AUTOSAR XML (schema 00046)
package /ComponentTypes
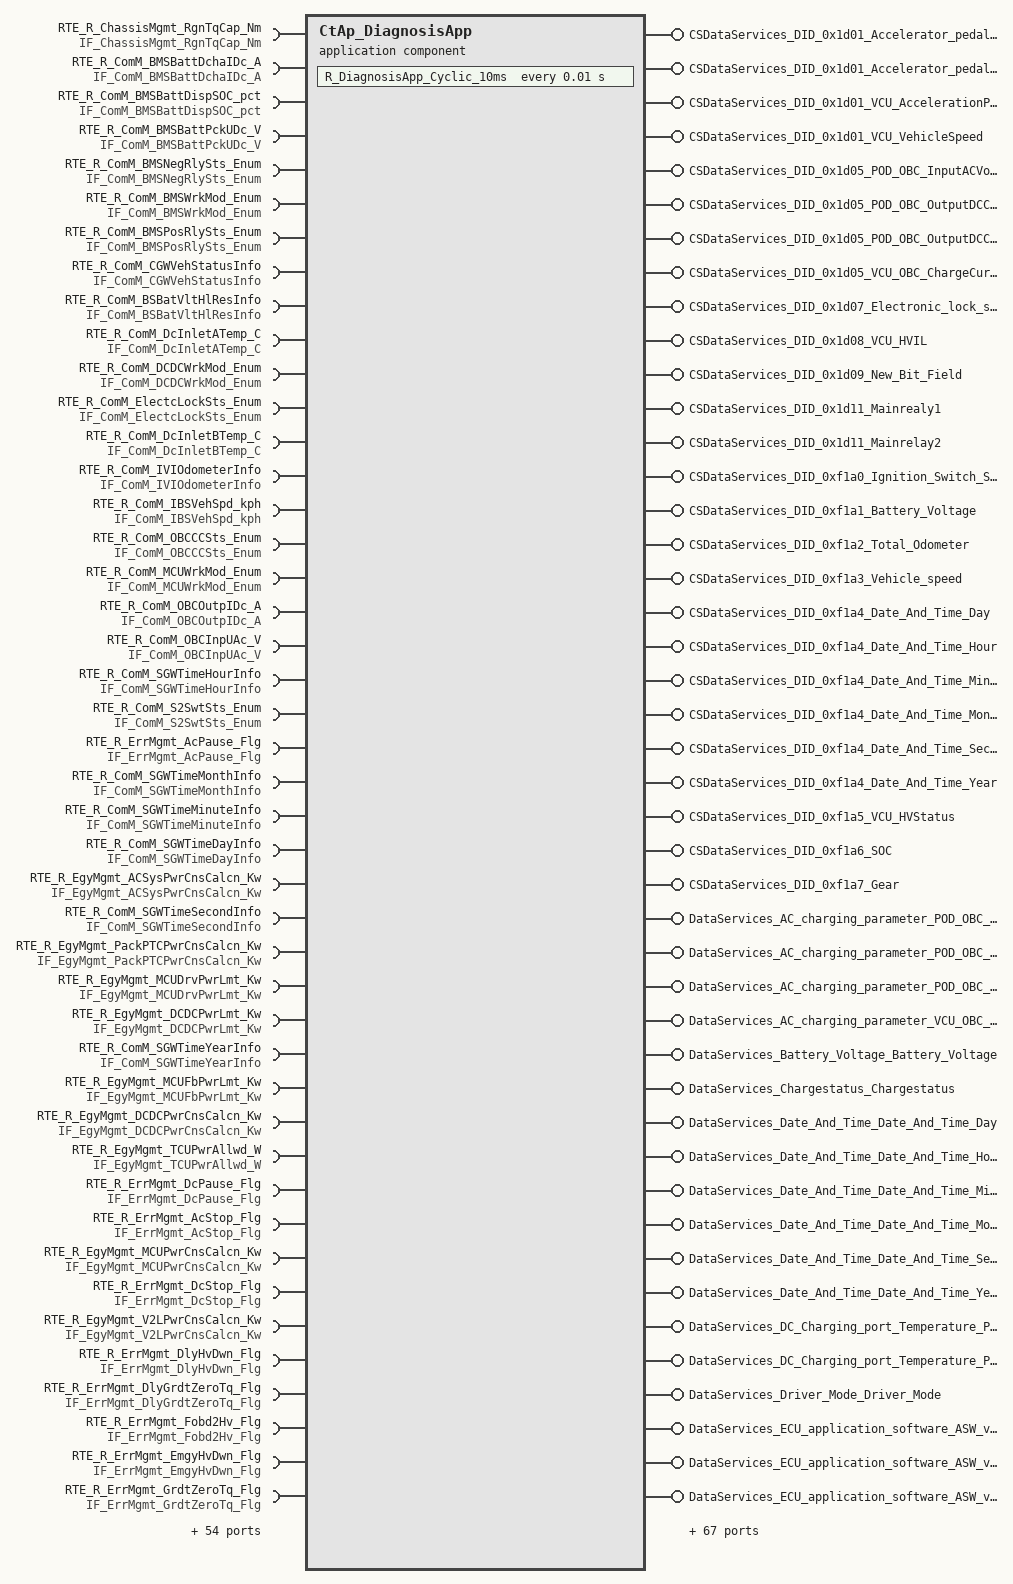
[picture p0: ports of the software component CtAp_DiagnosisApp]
  application sw component type CtAp_DiagnosisApp
    67 x require port:
      RTE_R_ChassisMgmt_RgnTqCap_Nm: nonqueued-receiver-com-spec{data-element=tec_ChassisMgmt_RgnTqCap_Nm, filter=data-filter-type=ALWAYS, init-value=0}, required-interface=IF_ChassisMgmt_RgnTqCap_Nm
      RTE_R_ComM_BMSBattDchaIDc_A: nonqueued-receiver-com-spec{data-element=tec_ComM_BMSBattDchaIDc_A, filter=data-filter-type=ALWAYS, init-value=0}, required-interface=IF_ComM_BMSBattDchaIDc_A
      RTE_R_ComM_BMSBattDispSOC_pct: nonqueued-receiver-com-spec{data-element=tec_ComM_BMSBattDispSOC_pct, filter=data-filter-type=ALWAYS, init-value=0}, required-interface=IF_ComM_BMSBattDispSOC_pct
      RTE_R_ComM_BMSBattPckUDc_V: nonqueued-receiver-com-spec{data-element=tec_ComM_BMSBattPckUDc_V, filter=data-filter-type=ALWAYS, init-value=0}, required-interface=IF_ComM_BMSBattPckUDc_V
      RTE_R_ComM_BMSNegRlySts_Enum: nonqueued-receiver-com-spec{data-element=tec_ComM_BMSNegRlySts_Enum, filter=data-filter-type=ALWAYS, init-value=0}, required-interface=IF_ComM_BMSNegRlySts_Enum
      RTE_R_ComM_BMSWrkMod_Enum: nonqueued-receiver-com-spec{data-element=tec_ComM_BMSWrkMod_Enum, filter=data-filter-type=ALWAYS, init-value=0}, required-interface=IF_ComM_BMSWrkMod_Enum
      RTE_R_ComM_BMSPosRlySts_Enum: nonqueued-receiver-com-spec{data-element=tec_ComM_BMSPosRlySts_Enum, filter=data-filter-type=ALWAYS, init-value=0}, required-interface=IF_ComM_BMSPosRlySts_Enum
      RTE_R_ComM_CGWVehStatusInfo: nonqueued-receiver-com-spec{data-element=tec_ComM_CGWVehStatusInfo, filter=data-filter-type=ALWAYS, init-value=0}, required-interface=IF_ComM_CGWVehStatusInfo
      RTE_R_ComM_BSBatVltHlResInfo: nonqueued-receiver-com-spec{data-element=tec_ComM_BSBatVltHlResInfo, filter=data-filter-type=ALWAYS, init-value=0}, required-interface=IF_ComM_BSBatVltHlResInfo
      RTE_R_ComM_DcInletATemp_C: nonqueued-receiver-com-spec{data-element=tec_ComM_DcInletATemp_C, filter=data-filter-type=ALWAYS, init-value=0}, required-interface=IF_ComM_DcInletATemp_C
      RTE_R_ComM_DCDCWrkMod_Enum: nonqueued-receiver-com-spec{data-element=tec_ComM_DCDCWrkMod_Enum, filter=data-filter-type=ALWAYS, init-value=0}, required-interface=IF_ComM_DCDCWrkMod_Enum
      RTE_R_ComM_ElectcLockSts_Enum: nonqueued-receiver-com-spec{data-element=tec_ComM_ElectcLockSts_Enum, filter=data-filter-type=ALWAYS, init-value=0}, required-interface=IF_ComM_ElectcLockSts_Enum
      RTE_R_ComM_DcInletBTemp_C: nonqueued-receiver-com-spec{data-element=tec_ComM_DcInletBTemp_C, filter=data-filter-type=ALWAYS, init-value=0}, required-interface=IF_ComM_DcInletBTemp_C
      RTE_R_ComM_IVIOdometerInfo: nonqueued-receiver-com-spec{data-element=tec_ComM_IVIOdometerInfo, filter=data-filter-type=ALWAYS, init-value=0}, required-interface=IF_ComM_IVIOdometerInfo
      RTE_R_ComM_IBSVehSpd_kph: nonqueued-receiver-com-spec{data-element=tec_ComM_IBSVehSpd_kph, filter=data-filter-type=ALWAYS, init-value=0}, required-interface=IF_ComM_IBSVehSpd_kph
      RTE_R_ComM_OBCCCSts_Enum: nonqueued-receiver-com-spec{data-element=tec_ComM_OBCCCSts_Enum, filter=data-filter-type=ALWAYS, init-value=0}, required-interface=IF_ComM_OBCCCSts_Enum
      RTE_R_ComM_MCUWrkMod_Enum: nonqueued-receiver-com-spec{data-element=tec_ComM_MCUWrkMod_Enum, filter=data-filter-type=ALWAYS, init-value=0}, required-interface=IF_ComM_MCUWrkMod_Enum
      RTE_R_ComM_OBCOutpIDc_A: nonqueued-receiver-com-spec{data-element=tec_ComM_OBCOutpIDc_A, filter=data-filter-type=ALWAYS, init-value=0}, required-interface=IF_ComM_OBCOutpIDc_A
      RTE_R_ComM_OBCInpUAc_V: nonqueued-receiver-com-spec{data-element=tec_ComM_OBCInpUAc_V, filter=data-filter-type=ALWAYS, init-value=0}, required-interface=IF_ComM_OBCInpUAc_V
      RTE_R_ComM_SGWTimeHourInfo: nonqueued-receiver-com-spec{data-element=tec_ComM_SGWTimeHourInfo, filter=data-filter-type=ALWAYS, init-value=0}, required-interface=IF_ComM_SGWTimeHourInfo
      RTE_R_ComM_S2SwtSts_Enum: nonqueued-receiver-com-spec{data-element=tec_ComM_S2SwtSts_Enum, filter=data-filter-type=ALWAYS, init-value=0}, required-interface=IF_ComM_S2SwtSts_Enum
      RTE_R_ErrMgmt_AcPause_Flg: nonqueued-receiver-com-spec{data-element=tec_ErrMgmt_AcPause_Flg, filter=data-filter-type=ALWAYS, init-value=0}, required-interface=IF_ErrMgmt_AcPause_Flg
      RTE_R_ComM_SGWTimeMonthInfo: nonqueued-receiver-com-spec{data-element=tec_ComM_SGWTimeMonthInfo, filter=data-filter-type=ALWAYS, init-value=0}, required-interface=IF_ComM_SGWTimeMonthInfo
      RTE_R_ComM_SGWTimeMinuteInfo: nonqueued-receiver-com-spec{data-element=tec_ComM_SGWTimeMinuteInfo, filter=data-filter-type=ALWAYS, init-value=0}, required-interface=IF_ComM_SGWTimeMinuteInfo
      RTE_R_ComM_SGWTimeDayInfo: nonqueued-receiver-com-spec{data-element=tec_ComM_SGWTimeDayInfo, filter=data-filter-type=ALWAYS, init-value=0}, required-interface=IF_ComM_SGWTimeDayInfo
      RTE_R_EgyMgmt_ACSysPwrCnsCalcn_Kw: nonqueued-receiver-com-spec{data-element=tec_EgyMgmt_ACSysPwrCnsCalcn_Kw, filter=data-filter-type=ALWAYS, init-value=0}, required-interface=IF_EgyMgmt_ACSysPwrCnsCalcn_Kw
      RTE_R_ComM_SGWTimeSecondInfo: nonqueued-receiver-com-spec{data-element=tec_ComM_SGWTimeSecondInfo, filter=data-filter-type=ALWAYS, init-value=0}, required-interface=IF_ComM_SGWTimeSecondInfo
      RTE_R_EgyMgmt_PackPTCPwrCnsCalcn_Kw: nonqueued-receiver-com-spec{data-element=tec_EgyMgmt_PackPTCPwrCnsCalcn_Kw, filter=data-filter-type=ALWAYS, init-value=0}, required-interface=IF_EgyMgmt_PackPTCPwrCnsCalcn_Kw
      RTE_R_EgyMgmt_MCUDrvPwrLmt_Kw: nonqueued-receiver-com-spec{data-element=tec_EgyMgmt_MCUDrvPwrLmt_Kw, filter=data-filter-type=ALWAYS, init-value=0}, required-interface=IF_EgyMgmt_MCUDrvPwrLmt_Kw
      RTE_R_EgyMgmt_DCDCPwrLmt_Kw: nonqueued-receiver-com-spec{data-element=tec_EgyMgmt_DCDCPwrLmt_Kw, filter=data-filter-type=ALWAYS, init-value=0}, required-interface=IF_EgyMgmt_DCDCPwrLmt_Kw
      RTE_R_ComM_SGWTimeYearInfo: nonqueued-receiver-com-spec{data-element=tec_ComM_SGWTimeYearInfo, filter=data-filter-type=ALWAYS, init-value=0}, required-interface=IF_ComM_SGWTimeYearInfo
      RTE_R_EgyMgmt_MCUFbPwrLmt_Kw: nonqueued-receiver-com-spec{data-element=tec_EgyMgmt_MCUFbPwrLmt_Kw, filter=data-filter-type=ALWAYS, init-value=0}, required-interface=IF_EgyMgmt_MCUFbPwrLmt_Kw
      RTE_R_EgyMgmt_DCDCPwrCnsCalcn_Kw: nonqueued-receiver-com-spec{data-element=tec_EgyMgmt_DCDCPwrCnsCalcn_Kw, filter=data-filter-type=ALWAYS, init-value=0}, required-interface=IF_EgyMgmt_DCDCPwrCnsCalcn_Kw
      RTE_R_EgyMgmt_TCUPwrAllwd_W: nonqueued-receiver-com-spec{data-element=tec_EgyMgmt_TCUPwrAllwd_W, filter=data-filter-type=ALWAYS, init-value=0}, required-interface=IF_EgyMgmt_TCUPwrAllwd_W
      RTE_R_ErrMgmt_DcPause_Flg: nonqueued-receiver-com-spec{data-element=tec_ErrMgmt_DcPause_Flg, filter=data-filter-type=ALWAYS, init-value=0}, required-interface=IF_ErrMgmt_DcPause_Flg
      RTE_R_ErrMgmt_AcStop_Flg: nonqueued-receiver-com-spec{data-element=tec_ErrMgmt_AcStop_Flg, filter=data-filter-type=ALWAYS, init-value=0}, required-interface=IF_ErrMgmt_AcStop_Flg
      RTE_R_EgyMgmt_MCUPwrCnsCalcn_Kw: nonqueued-receiver-com-spec{data-element=tec_EgyMgmt_MCUPwrCnsCalcn_Kw, filter=data-filter-type=ALWAYS, init-value=0}, required-interface=IF_EgyMgmt_MCUPwrCnsCalcn_Kw
      RTE_R_ErrMgmt_DcStop_Flg: nonqueued-receiver-com-spec{data-element=tec_ErrMgmt_DcStop_Flg, filter=data-filter-type=ALWAYS, init-value=0}, required-interface=IF_ErrMgmt_DcStop_Flg
      RTE_R_EgyMgmt_V2LPwrCnsCalcn_Kw: nonqueued-receiver-com-spec{data-element=tec_EgyMgmt_V2LPwrCnsCalcn_Kw, filter=data-filter-type=ALWAYS, init-value=0}, required-interface=IF_EgyMgmt_V2LPwrCnsCalcn_Kw
      RTE_R_ErrMgmt_DlyHvDwn_Flg: nonqueued-receiver-com-spec{data-element=tec_ErrMgmt_DlyHvDwn_Flg, filter=data-filter-type=ALWAYS, init-value=0}, required-interface=IF_ErrMgmt_DlyHvDwn_Flg
      RTE_R_ErrMgmt_DlyGrdtZeroTq_Flg: nonqueued-receiver-com-spec{data-element=tec_ErrMgmt_DlyGrdtZeroTq_Flg, filter=data-filter-type=ALWAYS, init-value=0}, required-interface=IF_ErrMgmt_DlyGrdtZeroTq_Flg
      RTE_R_ErrMgmt_Fobd2Hv_Flg: nonqueued-receiver-com-spec{data-element=tec_ErrMgmt_Fobd2Hv_Flg, filter=data-filter-type=ALWAYS, init-value=0}, required-interface=IF_ErrMgmt_Fobd2Hv_Flg
      RTE_R_ErrMgmt_EmgyHvDwn_Flg: nonqueued-receiver-com-spec{data-element=tec_ErrMgmt_EmgyHvDwn_Flg, filter=data-filter-type=ALWAYS, init-value=0}, required-interface=IF_ErrMgmt_EmgyHvDwn_Flg
      RTE_R_ErrMgmt_GrdtZeroTq_Flg: nonqueued-receiver-com-spec{data-element=tec_ErrMgmt_GrdtZeroTq_Flg, filter=data-filter-type=ALWAYS, init-value=0}, required-interface=IF_ErrMgmt_GrdtZeroTq_Flg
      RTE_R_ErrMgmt_FobdEgyRcov_Flg: nonqueued-receiver-com-spec{data-element=tec_ErrMgmt_FobdEgyRcov_Flg, filter=data-filter-type=ALWAYS, init-value=0}, required-interface=IF_ErrMgmt_FobdEgyRcov_Flg
      RTE_R_ErrMgmt_ImdtZeroTq_Flg: nonqueued-receiver-com-spec{data-element=tec_ErrMgmt_ImdtZeroTq_Flg, filter=data-filter-type=ALWAYS, init-value=0}, required-interface=IF_ErrMgmt_ImdtZeroTq_Flg
      RTE_R_ErrMgmt_V2LStop_Flg: nonqueued-receiver-com-spec{data-element=tec_ErrMgmt_V2LStop_Flg, filter=data-filter-type=ALWAYS, init-value=0}, required-interface=IF_ErrMgmt_V2LStop_Flg
      RTE_R_ErrMgmt_HvDwn_Flg: nonqueued-receiver-com-spec{data-element=tec_ErrMgmt_HvDwn_Flg, filter=data-filter-type=ALWAYS, init-value=0}, required-interface=IF_ErrMgmt_HvDwn_Flg
      RTE_R_ErrMgmt_VehSpdLimErrLv5_Flg: nonqueued-receiver-com-spec{data-element=tec_ErrMgmt_VehSpdLimErrLv5_Flg, filter=data-filter-type=ALWAYS, init-value=0}, required-interface=IF_ErrMgmt_VehSpdLimErrLv5_Flg
      RTE_R_ErrMgmt_VehErrLvl_Enum: nonqueued-receiver-com-spec{data-element=tec_ErrMgmt_VehErrLvl_Enum, filter=data-filter-type=ALWAYS, init-value=0}, required-interface=IF_ErrMgmt_VehErrLvl_Enum
      RTE_R_FctSftyMon_ActGear_Enum: nonqueued-receiver-com-spec{data-element=tec_FctSftyMon_ActGear_Enum, filter=data-filter-type=ALWAYS, init-value=0}, required-interface=IF_FctSftyMon_ActGear_Enum
      RTE_R_ErrMgmt_VehSpdLimErrLv6_Flg: nonqueued-receiver-com-spec{data-element=tec_ErrMgmt_VehSpdLimErrLv6_Flg, filter=data-filter-type=ALWAYS, init-value=0}, required-interface=IF_ErrMgmt_VehSpdLimErrLv6_Flg
      RTE_R_HvMgmt_ReqModBMS_Enum: nonqueued-receiver-com-spec{data-element=tec_HvMgmt_ReqModBMS_Enum, filter=data-filter-type=ALWAYS, init-value=0}, required-interface=IF_HvMgmt_ReqModBMS_Enum
      RTE_R_IOAbs_AccrPedlRdnRaw_mV: nonqueued-receiver-com-spec{data-element=tec_IOAbs_AccrPedlRdnRaw_mV, filter=data-filter-type=ALWAYS, init-value=0}, required-interface=IF_IOAbs_AccrPedlRdnRaw_mV
      RTE_R_IOAbs_AccrPedlMaiRaw_mV: nonqueued-receiver-com-spec{data-element=tec_IOAbs_AccrPedlMaiRaw_mV, filter=data-filter-type=ALWAYS, init-value=0}, required-interface=IF_IOAbs_AccrPedlMaiRaw_mV
      RTE_R_IOAbs_BSBattUDc_V: nonqueued-receiver-com-spec{data-element=tec_IOAbs_BSBattUDc_V, filter=data-filter-type=ALWAYS, init-value=0}, required-interface=IF_IOAbs_BSBattUDc_V
      RTE_R_ModMgmt_ActDrvMod_Enum: nonqueued-receiver-com-spec{data-element=tec_ModMgmt_ActDrvMod_Enum, filter=data-filter-type=ALWAYS, init-value=0}, required-interface=IF_ModMgmt_ActDrvMod_Enum
      RTE_R_IOAbs_HVILPwmFrq_Hz: nonqueued-receiver-com-spec{data-element=tec_IOAbs_HVILPwmFrq_Hz, filter=data-filter-type=ALWAYS, init-value=0}, required-interface=IF_IOAbs_HVILPwmFrq_Hz
      RTE_R_ModMgmt_HvSts_Enum: nonqueued-receiver-com-spec{data-element=tec_ModMgmt_HvSts_Enum, filter=data-filter-type=ALWAYS, init-value=0}, required-interface=IF_ModMgmt_HvSts_Enum
      RTE_R_OBCMgmt_ReqOBCIDc_A: nonqueued-receiver-com-spec{data-element=tec_OBCMgmt_ReqOBCIDc_A, filter=data-filter-type=ALWAYS, init-value=0}, required-interface=IF_OBCMgmt_ReqOBCIDc_A
      RTE_R_OBCMgmt_ElectcLockCtrlCmd_Enum: nonqueued-receiver-com-spec{data-element=tec_OBCMgmt_ElectcLockCtrlCmd_Enum, filter=data-filter-type=ALWAYS, init-value=0}, required-interface=IF_OBCMgmt_ElectcLockCtrlCmd_Enum
      RTE_R_TorqPahMgmt_EmacQstyMaxTq_Nm: nonqueued-receiver-com-spec{data-element=tec_TorqPahMgmt_EmacQstyMaxTq_Nm, filter=data-filter-type=ALWAYS, init-value=0}, required-interface=IF_TorqPahMgmt_EmacQstyMaxTq_Nm
      RTE_R_OBCMgmt_S2SwtCtrlCmd_Enum: nonqueued-receiver-com-spec{data-element=tec_OBCMgmt_S2SwtCtrlCmd_Enum, filter=data-filter-type=ALWAYS, init-value=0}, required-interface=IF_OBCMgmt_S2SwtCtrlCmd_Enum
      RTE_R_TorqPahMgmt_EmacQstyMinTq_Nm: nonqueued-receiver-com-spec{data-element=tec_TorqPahMgmt_EmacQstyMinTq_Nm, filter=data-filter-type=ALWAYS, init-value=0}, required-interface=IF_TorqPahMgmt_EmacQstyMinTq_Nm
      RTE_R_TorqPahMgmt_DesMotTq_Nm: nonqueued-receiver-com-spec{data-element=tec_TorqPahMgmt_DesMotTq_Nm, filter=data-filter-type=ALWAYS, init-value=0}, required-interface=IF_TorqPahMgmt_DesMotTq_Nm
      RTE_R_VehMot_VehSpd_kph: nonqueued-receiver-com-spec{data-element=tec_VehMot_VehSpd_kph, filter=data-filter-type=ALWAYS, init-value=0}, required-interface=IF_VehMot_VehSpd_kph
      RTE_R_ComM_OBCOutpUDc_V: nonqueued-receiver-com-spec{data-element=tec_ComM_OBCOutpUDc_V, filter=data-filter-type=ALWAYS, init-value=0}, required-interface=IF_ComM_OBCOutpUDc_V
    81 x provide port:
      CSDataServices_DID_0x1d01_Accelerator_pedal_sensor_1_voltage: server-com-spec{operation=ReadData, queue-length=1}, provided-interface=CSDataServices_DID_0x1d01_Accelerator_pedal_sensor_1_voltage
      CSDataServices_DID_0x1d01_Accelerator_pedal_sensor_2_voltage: server-com-spec{operation=ReadData, queue-length=1}, provided-interface=CSDataServices_DID_0x1d01_Accelerator_pedal_sensor_2_voltage
      CSDataServices_DID_0x1d01_VCU_AccelerationPedal: server-com-spec{operation=ReadData, queue-length=1}, provided-interface=CSDataServices_DID_0x1d01_VCU_AccelerationPedal
      CSDataServices_DID_0x1d01_VCU_VehicleSpeed: server-com-spec{operation=ReadData, queue-length=1}, provided-interface=CSDataServices_DID_0x1d01_VCU_VehicleSpeed
      CSDataServices_DID_0x1d05_POD_OBC_InputACVoltage: server-com-spec{operation=ReadData, queue-length=1}, provided-interface=CSDataServices_DID_0x1d05_POD_OBC_InputACVoltage
      CSDataServices_DID_0x1d05_POD_OBC_OutputDCChargeCurrent: server-com-spec{operation=ReadData, queue-length=1}, provided-interface=CSDataServices_DID_0x1d05_POD_OBC_OutputDCChargeCurrent
      CSDataServices_DID_0x1d05_POD_OBC_OutputDCChargeVoltage: server-com-spec{operation=ReadData, queue-length=1}, provided-interface=CSDataServices_DID_0x1d05_POD_OBC_OutputDCChargeVoltage
      CSDataServices_DID_0x1d05_VCU_OBC_ChargeCurrentCommand: server-com-spec{operation=ReadData, queue-length=1}, provided-interface=CSDataServices_DID_0x1d05_VCU_OBC_ChargeCurrentCommand
      CSDataServices_DID_0x1d07_Electronic_lock_state: server-com-spec{operation=ReadData, queue-length=1}, provided-interface=CSDataServices_DID_0x1d07_Electronic_lock_state
      CSDataServices_DID_0x1d08_VCU_HVIL: server-com-spec{operation=ReadData, queue-length=1}, provided-interface=CSDataServices_DID_0x1d08_VCU_HVIL
      CSDataServices_DID_0x1d09_New_Bit_Field: server-com-spec{operation=ReadData, queue-length=1}, provided-interface=CSDataServices_DID_0x1d09_New_Bit_Field
      CSDataServices_DID_0x1d11_Mainrealy1: server-com-spec{operation=ReadData, queue-length=1}, provided-interface=CSDataServices_DID_0x1d11_Mainrealy1
      CSDataServices_DID_0x1d11_Mainrelay2: server-com-spec{operation=ReadData, queue-length=1}, provided-interface=CSDataServices_DID_0x1d11_Mainrelay2
      CSDataServices_DID_0xf1a0_Ignition_Switch_Signal: server-com-spec{operation=ReadData, queue-length=1}, provided-interface=CSDataServices_DID_0xf1a0_Ignition_Switch_Signal
      CSDataServices_DID_0xf1a1_Battery_Voltage: server-com-spec{operation=ReadData, queue-length=1}, provided-interface=CSDataServices_DID_0xf1a1_Battery_Voltage
      CSDataServices_DID_0xf1a2_Total_Odometer: server-com-spec{operation=ReadData, queue-length=1}, provided-interface=CSDataServices_DID_0xf1a2_Total_Odometer
      CSDataServices_DID_0xf1a3_Vehicle_speed: server-com-spec{operation=ReadData, queue-length=1}, provided-interface=CSDataServices_DID_0xf1a3_Vehicle_speed
      CSDataServices_DID_0xf1a4_Date_And_Time_Day: server-com-spec{operation=ReadData, queue-length=1}, provided-interface=CSDataServices_DID_0xf1a4_Date_And_Time_Day
      CSDataServices_DID_0xf1a4_Date_And_Time_Hour: server-com-spec{operation=ReadData, queue-length=1}, provided-interface=CSDataServices_DID_0xf1a4_Date_And_Time_Hour
      CSDataServices_DID_0xf1a4_Date_And_Time_Minute: server-com-spec{operation=ReadData, queue-length=1}, provided-interface=CSDataServices_DID_0xf1a4_Date_And_Time_Minute
      CSDataServices_DID_0xf1a4_Date_And_Time_Month: server-com-spec{operation=ReadData, queue-length=1}, provided-interface=CSDataServices_DID_0xf1a4_Date_And_Time_Month
      CSDataServices_DID_0xf1a4_Date_And_Time_Second: server-com-spec{operation=ReadData, queue-length=1}, provided-interface=CSDataServices_DID_0xf1a4_Date_And_Time_Second
      CSDataServices_DID_0xf1a4_Date_And_Time_Year: server-com-spec{operation=ReadData, queue-length=1}, provided-interface=CSDataServices_DID_0xf1a4_Date_And_Time_Year
      CSDataServices_DID_0xf1a5_VCU_HVStatus: server-com-spec{operation=ReadData, queue-length=1}, provided-interface=CSDataServices_DID_0xf1a5_VCU_HVStatus
      CSDataServices_DID_0xf1a6_SOC: server-com-spec{operation=ReadData, queue-length=1}, provided-interface=CSDataServices_DID_0xf1a6_SOC
      CSDataServices_DID_0xf1a7_Gear: server-com-spec{operation=ReadData, queue-length=1}, provided-interface=CSDataServices_DID_0xf1a7_Gear
      DataServices_AC_charging_parameter_POD_OBC_InputACVoltage: provided-com-specs=[{operation=ConditionCheckRead, queue-length=1}, {operation=ReadData, queue-length=1}], provided-interface=DataServices_AC_charging_parameter_POD_OBC_InputACVoltage
      DataServices_AC_charging_parameter_POD_OBC_OutputDCChargeCurrent: provided-com-specs=[{operation=ConditionCheckRead, queue-length=1}, {operation=ReadData, queue-length=1}], provided-interface=DataServices_AC_charging_parameter_POD_OBC_OutputDCChargeCurrent
      DataServices_AC_charging_parameter_POD_OBC_OutputDCChargeVoltage: provided-com-specs=[{operation=ConditionCheckRead, queue-length=1}, {operation=ReadData, queue-length=1}], provided-interface=DataServices_AC_charging_parameter_POD_OBC_OutputDCChargeVoltage
      DataServices_AC_charging_parameter_VCU_OBC_ChargeCurrentCommand: provided-com-specs=[{operation=ConditionCheckRead, queue-length=1}, {operation=ReadData, queue-length=1}], provided-interface=DataServices_AC_charging_parameter_VCU_OBC_ChargeCurrentCommand
      DataServices_Battery_Voltage_Battery_Voltage: provided-com-specs=[{operation=ConditionCheckRead, queue-length=1}, {operation=ReadData, queue-length=1}], provided-interface=DataServices_Battery_Voltage_Battery_Voltage
      DataServices_Chargestatus_Chargestatus: provided-com-specs=[{operation=ConditionCheckRead, queue-length=1}, {operation=ReadData, queue-length=1}], provided-interface=DataServices_Chargestatus_Chargestatus
      DataServices_Date_And_Time_Date_And_Time_Day: provided-com-specs=[{operation=ConditionCheckRead, queue-length=1}, {operation=ReadData, queue-length=1}], provided-interface=DataServices_Date_And_Time_Date_And_Time_Day
      DataServices_Date_And_Time_Date_And_Time_Hour: provided-com-specs=[{operation=ConditionCheckRead, queue-length=1}, {operation=ReadData, queue-length=1}], provided-interface=DataServices_Date_And_Time_Date_And_Time_Hour
      DataServices_Date_And_Time_Date_And_Time_Minute: provided-com-specs=[{operation=ConditionCheckRead, queue-length=1}, {operation=ReadData, queue-length=1}], provided-interface=DataServices_Date_And_Time_Date_And_Time_Minute
      DataServices_Date_And_Time_Date_And_Time_Month: provided-com-specs=[{operation=ConditionCheckRead, queue-length=1}, {operation=ReadData, queue-length=1}], provided-interface=DataServices_Date_And_Time_Date_And_Time_Month
      DataServices_Date_And_Time_Date_And_Time_Second: provided-com-specs=[{operation=ConditionCheckRead, queue-length=1}, {operation=ReadData, queue-length=1}], provided-interface=DataServices_Date_And_Time_Date_And_Time_Second
      DataServices_Date_And_Time_Date_And_Time_Year: provided-com-specs=[{operation=ConditionCheckRead, queue-length=1}, {operation=ReadData, queue-length=1}], provided-interface=DataServices_Date_And_Time_Date_And_Time_Year
      DataServices_DC_Charging_port_Temperature_POD_DCInletTempA: provided-com-specs=[{operation=ConditionCheckRead, queue-length=1}, {operation=ReadData, queue-length=1}], provided-interface=DataServices_DC_Charging_port_Temperature_POD_DCInletTempA
      DataServices_DC_Charging_port_Temperature_POD_DCInletTempB: provided-com-specs=[{operation=ConditionCheckRead, queue-length=1}, {operation=ReadData, queue-length=1}], provided-interface=DataServices_DC_Charging_port_Temperature_POD_DCInletTempB
      DataServices_Driver_Mode_Driver_Mode: provided-com-specs=[{operation=ConditionCheckRead, queue-length=1}, {operation=ReadData, queue-length=1}], provided-interface=DataServices_Driver_Mode_Driver_Mode
      DataServices_ECU_application_software_ASW_version_number_Major_release: provided-com-specs=[{operation=ConditionCheckRead, queue-length=1}, {operation=ReadData, queue-length=1}], provided-interface=DataServices_ECU_application_software_ASW_version_number_Major_release
      DataServices_ECU_application_software_ASW_version_number_Minor_release: provided-com-specs=[{operation=ConditionCheckRead, queue-length=1}, {operation=ReadData, queue-length=1}], provided-interface=DataServices_ECU_application_software_ASW_version_number_Minor_release
      DataServices_ECU_application_software_ASW_version_number_No_functional_content_change: provided-com-specs=[{operation=ConditionCheckRead, queue-length=1}, {operation=ReadData, queue-length=1}], provided-interface=DataServices_ECU_application_software_ASW_version_number_No_functional_content_change
      DataServices_Electronic_lock_state_Electronic_lock_state: provided-com-specs=[{operation=ConditionCheckRead, queue-length=1}, {operation=ReadData, queue-length=1}], provided-interface=DataServices_Electronic_lock_state_Electronic_lock_state
      DataServices_Gear_Gear: provided-com-specs=[{operation=ConditionCheckRead, queue-length=1}, {operation=ReadData, queue-length=1}], provided-interface=DataServices_Gear_Gear
      DataServices_HV_part_work_mode_HV_part_work_mode1: provided-com-specs=[{operation=ConditionCheckRead, queue-length=1}, {operation=ReadData, queue-length=1}], provided-interface=DataServices_HV_part_work_mode_HV_part_work_mode1
      DataServices_HV_part_work_mode_HV_part_work_mode2: provided-com-specs=[{operation=ConditionCheckRead, queue-length=1}, {operation=ReadData, queue-length=1}], provided-interface=DataServices_HV_part_work_mode_HV_part_work_mode2
      DataServices_HV_Status_and_Charging_Status_HV_status_and_charging_status: provided-com-specs=[{operation=ConditionCheckRead, queue-length=1}, {operation=ReadData, queue-length=1}], provided-interface=DataServices_HV_Status_and_Charging_Status_HV_status_and_charging_status
      DataServices_PWT_vehicle_fault_PWT_ErrorLevel{1..3}: provided-com-specs=[{operation=ConditionCheckRead, queue-length=1}, {operation=ReadData, queue-length=1}], provided-interface=DataServices_PWT_vehicle_fault_PWT_ErrorLevel{1..3}
      DataServices_SOC_SOC: provided-com-specs=[{operation=ConditionCheckRead, queue-length=1}, {operation=ReadData, queue-length=1}], provided-interface=DataServices_SOC_SOC
      DataServices_Total_Odometer_Total_Odometer: provided-com-specs=[{operation=ConditionCheckRead, queue-length=1}, {operation=ReadData, queue-length=1}], provided-interface=DataServices_Total_Odometer_Total_Odometer
      DataServices_VCU_AccPealparameter_Accelerator_pedal_sensor_1_voltage: provided-com-specs=[{operation=ConditionCheckRead, queue-length=1}, {operation=ReadData, queue-length=1}], provided-interface=DataServices_VCU_AccPealparameter_Accelerator_pedal_sensor_1_voltage
      DataServices_VCU_AccPealparameter_Accelerator_pedal_sensor_2_voltage: provided-com-specs=[{operation=ConditionCheckRead, queue-length=1}, {operation=ReadData, queue-length=1}], provided-interface=DataServices_VCU_AccPealparameter_Accelerator_pedal_sensor_2_voltage
      DataServices_VCU_AccPealparameter_VCU_AccelerationPedal: provided-com-specs=[{operation=ConditionCheckRead, queue-length=1}, {operation=ReadData, queue-length=1}], provided-interface=DataServices_VCU_AccPealparameter_VCU_AccelerationPedal
      DataServices_VCU_AccPealparameter_VCU_VehicleSpeed: provided-com-specs=[{operation=ConditionCheckRead, queue-length=1}, {operation=ReadData, queue-length=1}], provided-interface=DataServices_VCU_AccPealparameter_VCU_VehicleSpeed
      DataServices_VCU_control_main_relay_Mainrealy1: provided-com-specs=[{operation=ConditionCheckRead, queue-length=1}, {operation=ReadData, queue-length=1}], provided-interface=DataServices_VCU_control_main_relay_Mainrealy1
      DataServices_VCU_control_main_relay_Mainrelay2: provided-com-specs=[{operation=ConditionCheckRead, queue-length=1}, {operation=ReadData, queue-length=1}], provided-interface=DataServices_VCU_control_main_relay_Mainrelay2
      DataServices_VCU_control_S2_status_New_Bit_Field: provided-com-specs=[{operation=ConditionCheckRead, queue-length=1}, {operation=ReadData, queue-length=1}], provided-interface=DataServices_VCU_control_S2_status_New_Bit_Field
      DataServices_VCU_HV_InterLock_PWM_pfrequency_VCU_HVIL: provided-com-specs=[{operation=ConditionCheckRead, queue-length=1}, {operation=ReadData, queue-length=1}], provided-interface=DataServices_VCU_HV_InterLock_PWM_pfrequency_VCU_HVIL
      DataServices_VCU_HVStatus_VCU_HVStatus: provided-com-specs=[{operation=ConditionCheckRead, queue-length=1}, {operation=ReadData, queue-length=1}], provided-interface=DataServices_VCU_HVStatus_VCU_HVStatus
      DataServices_VCU_PowerMaxAllowed_parameter1_MCUPowerLimit: provided-com-specs=[{operation=ConditionCheckRead, queue-length=1}, {operation=ReadData, queue-length=1}], provided-interface=DataServices_VCU_PowerMaxAllowed_parameter1_MCUPowerLimit
      DataServices_VCU_PowerMaxAllowed_parameter1_VCU_DCDCPowerLimit: provided-com-specs=[{operation=ConditionCheckRead, queue-length=1}, {operation=ReadData, queue-length=1}], provided-interface=DataServices_VCU_PowerMaxAllowed_parameter1_VCU_DCDCPowerLimit
      DataServices_VCU_PowerMaxAllowed_parameter1_VCU_DisChgPowerLimit: provided-com-specs=[{operation=ConditionCheckRead, queue-length=1}, {operation=ReadData, queue-length=1}], provided-interface=DataServices_VCU_PowerMaxAllowed_parameter1_VCU_DisChgPowerLimit
      DataServices_VCU_PowerMaxAllowed_parameter1_VCU_TCUPowerAllowed: provided-com-specs=[{operation=ConditionCheckRead, queue-length=1}, {operation=ReadData, queue-length=1}], provided-interface=DataServices_VCU_PowerMaxAllowed_parameter1_VCU_TCUPowerAllowed
      DataServices_VCU_PowerMaxAllowed_parameter2_BMSChgPowerLimit: provided-com-specs=[{operation=ConditionCheckRead, queue-length=1}, {operation=ReadData, queue-length=1}], provided-interface=DataServices_VCU_PowerMaxAllowed_parameter2_BMSChgPowerLimit
      DataServices_VCU_PowerMaxAllowed_parameter2_BMSDisChgPowerLimit: provided-com-specs=[{operation=ConditionCheckRead, queue-length=1}, {operation=ReadData, queue-length=1}], provided-interface=DataServices_VCU_PowerMaxAllowed_parameter2_BMSDisChgPowerLimit
      DataServices_VCU_PowerMaxAllowed_parameter2_MCUFeedbackPowerLimit: provided-com-specs=[{operation=ConditionCheckRead, queue-length=1}, {operation=ReadData, queue-length=1}], provided-interface=DataServices_VCU_PowerMaxAllowed_parameter2_MCUFeedbackPowerLimit
      DataServices_VCU_PowerMaxAllowed_parameter3_ACSystemPower: provided-com-specs=[{operation=ConditionCheckRead, queue-length=1}, {operation=ReadData, queue-length=1}], provided-interface=DataServices_VCU_PowerMaxAllowed_parameter3_ACSystemPower
      DataServices_VCU_PowerMaxAllowed_parameter3_DCDCPower: provided-com-specs=[{operation=ConditionCheckRead, queue-length=1}, {operation=ReadData, queue-length=1}], provided-interface=DataServices_VCU_PowerMaxAllowed_parameter3_DCDCPower
      DataServices_VCU_PowerMaxAllowed_parameter3_MCUPower: provided-com-specs=[{operation=ConditionCheckRead, queue-length=1}, {operation=ReadData, queue-length=1}], provided-interface=DataServices_VCU_PowerMaxAllowed_parameter3_MCUPower
      DataServices_VCU_PowerMaxAllowed_parameter3_PackPTCPower: provided-com-specs=[{operation=ConditionCheckRead, queue-length=1}, {operation=ReadData, queue-length=1}], provided-interface=DataServices_VCU_PowerMaxAllowed_parameter3_PackPTCPower
      DataServices_VCU_PowerMaxAllowed_parameter3_V2LPower: provided-com-specs=[{operation=ConditionCheckRead, queue-length=1}, {operation=ReadData, queue-length=1}], provided-interface=DataServices_VCU_PowerMaxAllowed_parameter3_V2LPower
      DataServices_VCU_Torque_parameter_Torque_MaxAllowed: provided-com-specs=[{operation=ConditionCheckRead, queue-length=1}, {operation=ReadData, queue-length=1}], provided-interface=DataServices_VCU_Torque_parameter_Torque_MaxAllowed
      DataServices_VCU_Torque_parameter_Torque_MinAllowed: provided-com-specs=[{operation=ConditionCheckRead, queue-length=1}, {operation=ReadData, queue-length=1}], provided-interface=DataServices_VCU_Torque_parameter_Torque_MinAllowed
      DataServices_VCU_Torque_parameter_VCU_MCUDesiredTorque: provided-com-specs=[{operation=ConditionCheckRead, queue-length=1}, {operation=ReadData, queue-length=1}], provided-interface=DataServices_VCU_Torque_parameter_VCU_MCUDesiredTorque
      DataServices_VCU_Torque_parameter_VCU_RegenTorqueCap: provided-com-specs=[{operation=ConditionCheckRead, queue-length=1}, {operation=ReadData, queue-length=1}], provided-interface=DataServices_VCU_Torque_parameter_VCU_RegenTorqueCap
      DataServices_Vehicle_speed_Vehicle_speed: provided-com-specs=[{operation=ConditionCheckRead, queue-length=1}, {operation=ReadData, queue-length=1}], provided-interface=DataServices_Vehicle_speed_Vehicle_speed
      DataServices_Vehicle_State_Ignition_Switch_Signal: provided-com-specs=[{operation=ConditionCheckRead, queue-length=1}, {operation=ReadData, queue-length=1}], provided-interface=DataServices_Vehicle_State_Ignition_Switch_Signal
    require port RTE_R_ComM_BMSBattFbIDc_A: nonqueued-receiver-com-spec{data-element=tec_ComM_BMSBattFbIDc_A, filter=data-filter-type=ALWAYS, init-value=0}, required-interface=IF_ComM_BMSBattFbIDc_A
    require port RTE_R_ErrMgmt_HvNormDwn_Flg: nonqueued-receiver-com-spec{data-element=tec_ErrMgmt_HvNormDwn_Flg, filter=data-filter-type=ALWAYS, init-value=0}, required-interface=IF_ErrMgmt_HvNormDwn_Flg
    require port RTE_R_ChassisMgmt_AccrPedlPosn_pct: nonqueued-receiver-com-spec{data-element=tec_ChassisMgmt_AccrPedlPosn_pct, filter=data-filter-type=ALWAYS, init-value=0}, required-interface=IF_ChassisMgmt_AccrPedlPosn_pct
    provide port DataServices_Read_Write_coding_data_string_CDS_Configuration: provided-interface=DataServices_Read_Write_coding_data_string_CDS_Configuration
      provided-com-specs:
        operation=WriteData, queue-length=1
        operation=ConditionCheckRead, queue-length=1
        operation=ReadData, queue-length=1
    provide port RTE_P_DiagApp_SpdLmtInfo: nonqueued-sender-com-spec{data-element=tec_DiagApp_SpdLmtInfo, init-value=0}, provided-interface=IF_DiagApp_SpdLmtInfo
    provide port RTE_P_DiagApp_TireRadiusInfo: nonqueued-sender-com-spec{data-element=tec_DiagApp_TireRadiusInfo, init-value=0}, provided-interface=IF_DiagApp_TireRadiusInfo
    require port RTE_R_VotMot_TireRadiusReadInfo: nonqueued-receiver-com-spec{data-element=tec_VotMot_TireRadiusReadInfo, filter=data-filter-type=ALWAYS, init-value=0}, required-interface=IF_VotMot_TireRadiusReadInfo
    require port RTE_R_TorqPahMgmt_SpdLmtReadInfo: nonqueued-receiver-com-spec{data-element=tec_TorqPahMgmt_SpdLmtReadInfo, filter=data-filter-type=ALWAYS, init-value=0}, required-interface=IF_TorqPahMgmt_SpdLmtReadInfo
    require port RTE_R_ChrMgmt_ChrgSts_Enum: nonqueued-receiver-com-spec{data-element=tec_ChrMgmt_ChrgSts_Enum, filter=data-filter-type=ALWAYS, init-value=0}, required-interface=IF_ChrMgmt_ChrgSts_Enum
    19 x provide port:
      RTE_P_DiagApp_SpdLmtUpdateInfo: nonqueued-sender-com-spec{data-element=tec_DiagApp_SpdLmtUpdateInfo, init-value=0}, provided-interface=IF_DiagApp_SpdLmtUpdateInfo
      RTE_P_DiagApp_TireRadiusUpdateInfo: nonqueued-sender-com-spec{data-element=tec_DiagApp_TireRadiusUpdateInfo, init-value=0}, provided-interface=IF_DiagApp_TireRadiusUpdateInfo
      DataServices_Read_Write_coding_data_string_CDS_Version_Byte_1: provided-interface=DataServices_Read_Write_coding_data_string_CDS_Version_Byte_1
        provided-com-specs:
          operation=WriteData, queue-length=1
          operation=ConditionCheckRead, queue-length=1
          operation=ReadData, queue-length=1
      DataServices_Read_Write_coding_data_string_CDS_Version_Byte_0: provided-interface=DataServices_Read_Write_coding_data_string_CDS_Version_Byte_0
        provided-com-specs:
          operation=WriteData, queue-length=1
          operation=ConditionCheckRead, queue-length=1
          operation=ReadData, queue-length=1
      DataServices_Read_Write_coding_data_string_CDS_Reserved3: provided-interface=DataServices_Read_Write_coding_data_string_CDS_Reserved3
        provided-com-specs:
          operation=WriteData, queue-length=1
          operation=ConditionCheckRead, queue-length=1
          operation=ReadData, queue-length=1
      DataServices_Read_Write_coding_data_string_CDS_Reserved2: provided-interface=DataServices_Read_Write_coding_data_string_CDS_Reserved2
        provided-com-specs:
          operation=WriteData, queue-length=1
          operation=ConditionCheckRead, queue-length=1
          operation=ReadData, queue-length=1
      DataServices_Read_Write_coding_data_string_CDS_Reserved1: provided-interface=DataServices_Read_Write_coding_data_string_CDS_Reserved1
        provided-com-specs:
          operation=WriteData, queue-length=1
          operation=ConditionCheckRead, queue-length=1
          operation=ReadData, queue-length=1
      DataServices_Read_Write_coding_data_string_CDS_CDS_Short_VIN_High_Byte_7: provided-interface=DataServices_Read_Write_coding_data_string_CDS_CDS_Short_VIN_High_Byte_7
        provided-com-specs:
          operation=WriteData, queue-length=1
          operation=ConditionCheckRead, queue-length=1
          operation=ReadData, queue-length=1
      DataServices_Read_Write_coding_data_string_CDS_CDS_Short_VIN_High_Byte_5: provided-interface=DataServices_Read_Write_coding_data_string_CDS_CDS_Short_VIN_High_Byte_5
        provided-com-specs:
          operation=WriteData, queue-length=1
          operation=ConditionCheckRead, queue-length=1
          operation=ReadData, queue-length=1
      DataServices_Read_Write_coding_data_string_CDS_CDS_Short_VIN_High_Byte_4: provided-interface=DataServices_Read_Write_coding_data_string_CDS_CDS_Short_VIN_High_Byte_4
        provided-com-specs:
          operation=WriteData, queue-length=1
          operation=ConditionCheckRead, queue-length=1
          operation=ReadData, queue-length=1
      DataServices_Read_Write_coding_data_string_CDS_CDS_Short_VIN_High_Byte_3: provided-interface=DataServices_Read_Write_coding_data_string_CDS_CDS_Short_VIN_High_Byte_3
        provided-com-specs:
          operation=WriteData, queue-length=1
          operation=ConditionCheckRead, queue-length=1
          operation=ReadData, queue-length=1
      DataServices_Read_Write_coding_data_string_CDS_CDS_Short_VIN_High_Byte_2: provided-interface=DataServices_Read_Write_coding_data_string_CDS_CDS_Short_VIN_High_Byte_2
        provided-com-specs:
          operation=WriteData, queue-length=1
          operation=ConditionCheckRead, queue-length=1
          operation=ReadData, queue-length=1
      DataServices_Read_Write_coding_data_string_CDS_CDS_Short_VIN_High_Byte_1: provided-interface=DataServices_Read_Write_coding_data_string_CDS_CDS_Short_VIN_High_Byte_1
        provided-com-specs:
          operation=WriteData, queue-length=1
          operation=ConditionCheckRead, queue-length=1
          operation=ReadData, queue-length=1
      DataServices_Read_Write_coding_data_string_CDS_CDS_Short_VIN_High_Byte_0: provided-interface=DataServices_Read_Write_coding_data_string_CDS_CDS_Short_VIN_High_Byte_0
        provided-com-specs:
          operation=WriteData, queue-length=1
          operation=ConditionCheckRead, queue-length=1
          operation=ReadData, queue-length=1
      DataServices_Read_Write_coding_data_string_CDS_CDS_Format_Byte_High_Byte_1: provided-interface=DataServices_Read_Write_coding_data_string_CDS_CDS_Format_Byte_High_Byte_1
        provided-com-specs:
          operation=WriteData, queue-length=1
          operation=ConditionCheckRead, queue-length=1
          operation=ReadData, queue-length=1
      DataServices_Read_Write_coding_data_string_CDS_CDS_Format_Byte_High_Byte_0: provided-interface=DataServices_Read_Write_coding_data_string_CDS_CDS_Format_Byte_High_Byte_0
        provided-com-specs:
          operation=WriteData, queue-length=1
          operation=ConditionCheckRead, queue-length=1
          operation=ReadData, queue-length=1
      DataServices_Read_Write_coding_data_string_CDS_CDS_CRC: provided-interface=DataServices_Read_Write_coding_data_string_CDS_CDS_CRC
        provided-com-specs:
          operation=WriteData, queue-length=1
          operation=ConditionCheckRead, queue-length=1
          operation=ReadData, queue-length=1
      RTE_P_DiagApp_DisableDCMReqInfo: nonqueued-sender-com-spec{data-element=tec_DiagApp_DisableDCMReqInfo, init-value=0}, provided-interface=IF_DiagApp_DisableDCMReqInfo
      RTE_P_DiagApp_ClearRangeEstNVMReqInfo: nonqueued-sender-com-spec{data-element=tec_DiagApp_ClearRangeEstNVMReqInfo, init-value=0}, provided-interface=IF_DiagApp_ClearRangeEstNVMReqInfo
    require port RTE_R_RngEst_ClearNVMSucessInfo: nonqueued-receiver-com-spec{data-element=tec_RngEst_ClearNVMSucessInfo, filter=data-filter-type=ALWAYS, init-value=0}, required-interface=IF_RngEst_ClearNVMSucessInfo
    provide port RTE_P_DiagApp_StayInRunReqInfo: nonqueued-sender-com-spec{data-element=tec_DiagApp_StayInRunReqInfo, init-value=0}, provided-interface=IF_DiagApp_StayInRunReqInfo
    10 x require port:
      RTE_R_EgyMgmt_V2LDisChgPwrLmtInfo: nonqueued-receiver-com-spec{data-element=tec_EgyMgmt_V2LDisChgPwrLmtInfo, filter=data-filter-type=ALWAYS, init-value=0}, required-interface=IF_EgyMgmt_V2LDisChgPwrLmtInfo
      RTE_R_ComM_NodComFailr: required-interface=IF_ComM_NodComFailr
        required-com-specs:
          data-element=tec_ComM_DCMRRNodComFailr_Flg, filter=data-filter-type=ALWAYS, init-value=0
          data-element=tec_ComM_DCMRLNodComFailr_Flg, filter=data-filter-type=ALWAYS, init-value=0
          data-element=tec_ComM_DCMFRNodComFailr_Flg, filter=data-filter-type=ALWAYS, init-value=0
          data-element=tec_ComM_DCMFLNodComFailr_Flg, filter=data-filter-type=ALWAYS, init-value=0
          data-element=tec_ComM_APTCNodComFailr_Flg, filter=data-filter-type=ALWAYS, init-value=0
          data-element=tec_ComM_ADCUNodComFailr_Flg, filter=data-filter-type=ALWAYS, init-value=0
          data-element=tec_ComM_ACUNodComFailr_Flg, filter=data-filter-type=ALWAYS, init-value=0
          data-element=tec_ComM_SGWNodComFailr_Flg, filter=data-filter-type=ALWAYS, init-value=0
          data-element=tec_ComM_CGWNodComFailr_Flg, filter=data-filter-type=ALWAYS, init-value=0
          data-element=tec_ComM_TCUNodComFailr_Flg, filter=data-filter-type=ALWAYS, init-value=0
          data-element=tec_ComM_BCMNodComFailr_Flg, filter=data-filter-type=ALWAYS, init-value=0
          data-element=tec_ComM_PRNDNodComFailr_Flg, filter=data-filter-type=ALWAYS, init-value=0
          data-element=tec_ComM_IVINodComFailr_Flg, filter=data-filter-type=ALWAYS, init-value=0
          data-element=tec_ComM_DCDCNodComFailr_Flg, filter=data-filter-type=ALWAYS, init-value=0
          data-element=tec_ComM_OBCNodComFailr_Flg, filter=data-filter-type=ALWAYS, init-value=0
          data-element=tec_ComM_CHIBSNodComFailr_Flg, filter=data-filter-type=ALWAYS, init-value=0
          data-element=tec_ComM_MCUNodComFailr_Flg, filter=data-filter-type=ALWAYS, init-value=0
          data-element=tec_ComM_EVCOMNodComFailr_Flg, filter=data-filter-type=ALWAYS, init-value=0
          data-element=tec_ComM_EPTIBSNodComFailr_Flg, filter=data-filter-type=ALWAYS, init-value=0
          data-element=tec_ComM_DCMNodComFailr_Flg, filter=data-filter-type=ALWAYS, init-value=0
          data-element=tec_ComM_BMSNodComFailr_Flg, filter=data-filter-type=ALWAYS, init-value=0
          data-element=tec_ComM_SGWCHNodComFailr_Flg, init-value=0
      RTE_R_ChrMgmt_PosRlyReqSts_Enum: nonqueued-receiver-com-spec{data-element=tec_ChrMgmt_PosRlyReqSts_Enum, filter=data-filter-type=ALWAYS, init-value=0}, required-interface=IF_ChrMgmt_PosRlyReqSts_Enum
      RTE_R_ComM_OBCChrgSts_Enum: nonqueued-receiver-com-spec{data-element=tec_ComM_OBCChrgSts_Enum, filter=data-filter-type=ALWAYS, init-value=0}, required-interface=IF_ComM_OBCChrgSts_Enum
      RTE_R_ChassisMgmt_AccrPedlRawPosnInfo: nonqueued-receiver-com-spec{data-element=tec_ChassisMgmt_AccrPedlRawPosnInfo, filter=data-filter-type=ALWAYS, init-value=0}, required-interface=IF_ChassisMgmt_AccrPedlRawPosnInfo
      SG_IBS_VCU_MotorControl_SigGroup: nonqueued-receiver-com-spec{data-element=SG_IBS_VCU_MotorControl_SigGroup, uses-end-to-end-protection=true, enable-update=true, filter=data-filter-type=ALWAYS, init-value=fields=[IBS_WLTorqueIncrReq:0, IBS_WLTorqueIncrReqSts:0, IBS_WLTorqueRedReq:0, IBS_WLTorqueRedReqSts:0, Checksum_090:0, MessageCounter_090:0]}, required-interface=SG_IBS_VCU_MotorControl_SigGroup
      RTE_R_VehMot_VehSpdABS_kph: nonqueued-receiver-com-spec{data-element=tec_VehMot_VehSpdABS_kph, filter=data-filter-type=ALWAYS, init-value=0}, required-interface=IF_VehMot_VehSpdABS_kph
      RTE_R_ComM_BSBatCrnt: nonqueued-receiver-com-spec{data-element=tec_ComM_BSBatCrnt, filter=data-filter-type=ALWAYS, init-value=0}, required-interface=IF_ComM_BSBatCrnt
      RTE_R_ComM_BSBattSOHInfo: nonqueued-receiver-com-spec{data-element=tec_ComM_BSBattSOHInfo, filter=data-filter-type=ALWAYS, init-value=0}, required-interface=IF_ComM_BSBattSOHInfo
      RTE_R_ComM_BSBattSOC_pct: nonqueued-receiver-com-spec{data-element=tec_ComM_BSBattSOC_pct, filter=data-filter-type=ALWAYS, init-value=0}, required-interface=IF_ComM_BSBattSOC_pct
    6 x provide port, all with provided-com-specs=[{operation=ConditionCheckRead, queue-length=1}, {operation=ReadData, queue-length=1}]:
      DataServices_BS_base_information4_VCU_BS_Hcurrent: provided-interface=DataServices_BS_base_information4_VCU_BS_Hcurrent
      DataServices_BS_base_information4_T_BATT: provided-interface=DataServices_BS_base_information4_T_BATT
      DataServices_BS_base_information4_SOH: provided-interface=DataServices_BS_base_information4_SOH
      DataServices_BS_base_information4_SOF_V2: provided-interface=DataServices_BS_base_information4_SOF_V2
      DataServices_BS_base_information4_SOF_V1: provided-interface=DataServices_BS_base_information4_SOF_V1
      DataServices_BS_base_information4_BS_SOC: provided-interface=DataServices_BS_base_information4_BS_SOC
    4 x require port:
      RTE_R_ComM_BSHCrnt: nonqueued-receiver-com-spec{data-element=tec_ComM_BSHCrnt, filter=data-filter-type=ALWAYS}, required-interface=IF_ComM_BSHCrnt
      RTE_R_ComM_BSBattTempInfo: nonqueued-receiver-com-spec{data-element=tec_ComM_BSBattTempInfo, filter=data-filter-type=ALWAYS, init-value=0}, required-interface=IF_ComM_BSBattTempInfo
      RTE_R_ComM_BSSOFV2Info: nonqueued-receiver-com-spec{data-element=tec_ComM_BSSOFV2Info, filter=data-filter-type=ALWAYS, init-value=0}, required-interface=IF_ComM_BSSOFV2Info
      RTE_R_ComM_BSSOFV1Info: nonqueued-receiver-com-spec{data-element=tec_ComM_BSSOFV1Info, filter=data-filter-type=ALWAYS, init-value=0}, required-interface=IF_ComM_BSSOFV1Info
    provide port DataServices_HV_part_fault_information_HV_part_fault_information3: provided-interface=DataServices_HV_part_fault_information_HV_part_fault_information3
      provided-com-specs:
        operation=WriteData, queue-length=1
        operation=ConditionCheckRead, queue-length=1
        operation=ReadData, queue-length=1
    provide port DataServices_HV_part_fault_information_HV_part_fault_information2: provided-interface=DataServices_HV_part_fault_information_HV_part_fault_information2
      provided-com-specs:
        operation=WriteData, queue-length=1
        operation=ConditionCheckRead, queue-length=1
        operation=ReadData, queue-length=1
    provide port DataServices_HV_part_fault_information_HV_part_fault_information1: provided-interface=DataServices_HV_part_fault_information_HV_part_fault_information1
      provided-com-specs:
        operation=WriteData, queue-length=1
        operation=ConditionCheckRead, queue-length=1
        operation=ReadData, queue-length=1
    10 x require port:
      RTE_R_ComM_BMSErrLvl_Enum: nonqueued-receiver-com-spec{data-element=tec_ComM_BMSErrLvl_Enum, filter=data-filter-type=ALWAYS, init-value=0}, required-interface=IF_ComM_BMSErrLvl_Enum
      RTE_R_ComM_DCDCErrLvl_Enum: nonqueued-receiver-com-spec{data-element=tec_ComM_DCDCErrLvl_Enum, filter=data-filter-type=ALWAYS, init-value=0}, required-interface=IF_ComM_DCDCErrLvl_Enum
      RTE_R_ComM_OBCErrLvl_Enum: nonqueued-receiver-com-spec{data-element=tec_ComM_OBCErrLvl_Enum, filter=data-filter-type=ALWAYS, init-value=0}, required-interface=IF_ComM_OBCErrLvl_Enum
      RTE_R_ComM_TCUErrLvl_Enum: nonqueued-receiver-com-spec{data-element=tec_ComM_TCUErrLvl_Enum, filter=data-filter-type=ALWAYS, init-value=0}, required-interface=IF_ComM_TCUErrLvl_Enum
      RTE_R_ComM_MCUErrLvl_Enum: nonqueued-receiver-com-spec{data-element=tec_ComM_MCUErrLvl_Enum, filter=data-filter-type=ALWAYS, init-value=0}, required-interface=IF_ComM_MCUErrLvl_Enum
      RTE_R_ComM_BMSHVILSts_Flg: nonqueued-receiver-com-spec{data-element=tec_ComM_BMSHVILSts_Flg, filter=data-filter-type=ALWAYS, init-value=0}, required-interface=IF_ComM_BMSHVILSts_Flg
      RTE_R_ComM_ACUCrashOutpSts_Enum: nonqueued-receiver-com-spec{data-element=tec_ComM_ACUCrashOutpSts_Enum, filter=data-filter-type=ALWAYS, init-value=0}, required-interface=IF_ComM_ACUCrashOutpSts_Enum
      RTE_R_ComM_BMSInslaErrLvl_Enum: nonqueued-receiver-com-spec{data-element=tec_ComM_BMSInslaErrLvl_Enum, filter=data-filter-type=ALWAYS, init-value=0}, required-interface=IF_ComM_BMSInslaErrLvl_Enum
      RTE_R_ErrMgmt_VCUHVILErr_Flg: nonqueued-receiver-com-spec{data-element=tec_ErrMgmt_VCUHVILErr_Flg, filter=data-filter-type=ALWAYS, init-value=0}, required-interface=IF_ErrMgmt_VCUHVILErr_Flg
      SOC_LIN01: nonqueued-receiver-com-spec{data-element=SOC_LIN01, filter=data-filter-type=ALWAYS, init-value=1}, required-interface=SOC_LIN01
    behavior CtAp_DiagnosisApp_InternalBehavior
      timing event TMT_R_DiagnosisApp_Cyclic_10ms: start-on-event=R_DiagnosisApp_Cyclic_10ms, period=0.01
      init event CtAp_DiagnosisApp_InitEvent: start-on-event=R_DiagnosisApp_Init
      205 x operation invoked event:
        OIT_CSDataServices_DID_0x1d05_POD_OBC_OutputDCChargeCurrent_ReadData_CSDataServices_DID_0x1d05_POD_OBC_OutputDCChargeCur3BD0F90E: start-on-event=CSDataServices_DID_0x1d05_POD_OBC_OutputDCChargeCurrent_ReadData, operation=CSDataServices_DID_0x1d05_POD_OBC_OutputDCChargeCurrent.ReadData
        OIT_CSDataServices_DID_0xf1a4_Date_And_Time_Year_ReadData_CSDataServices_DID_0xf1a4_Date_And_Time_Year_ReadData: start-on-event=CSDataServices_DID_0xf1a4_Date_And_Time_Year_ReadData, operation=CSDataServices_DID_0xf1a4_Date_And_Time_Year.ReadData
        OIT_CSDataServices_DID_0x1d01_VCU_VehicleSpeed_ReadData_CSDataServices_DID_0x1d01_VCU_VehicleSpeed_ReadData: start-on-event=CSDataServices_DID_0x1d01_VCU_VehicleSpeed_ReadData, operation=CSDataServices_DID_0x1d01_VCU_VehicleSpeed.ReadData
        OIT_CSDataServices_DID_0x1d08_VCU_HVIL_ReadData_CSDataServices_DID_0x1d08_VCU_HVIL_ReadData: start-on-event=CSDataServices_DID_0x1d08_VCU_HVIL_ReadData, operation=CSDataServices_DID_0x1d08_VCU_HVIL.ReadData
        OIT_CSDataServices_DID_0x1d11_Mainrelay2_ReadData_CSDataServices_DID_0x1d11_Mainrelay2_ReadData: start-on-event=CSDataServices_DID_0x1d11_Mainrelay2_ReadData, operation=CSDataServices_DID_0x1d11_Mainrelay2.ReadData
        OIT_CSDataServices_DID_0x1d07_Electronic_lock_state_ReadData_CSDataServices_DID_0x1d07_Electronic_lock_state_ReadData: start-on-event=CSDataServices_DID_0x1d07_Electronic_lock_state_ReadData, operation=CSDataServices_DID_0x1d07_Electronic_lock_state.ReadData
        OIT_CSDataServices_DID_0x1d01_Accelerator_pedal_sensor_2_voltage_ReadData_CSDataServices_DID_0x1d01_Accelerator_pedal_seEE330965: start-on-event=CSDataServices_DID_0x1d01_Accelerator_pedal_sensor_2_voltage_ReadData, operation=CSDataServices_DID_0x1d01_Accelerator_pedal_sensor_2_voltage.ReadData
        OIT_CSDataServices_DID_0x1d09_New_Bit_Field_ReadData_CSDataServices_DID_0x1d09_New_Bit_Field_ReadData: start-on-event=CSDataServices_DID_0x1d09_New_Bit_Field_ReadData, operation=CSDataServices_DID_0x1d09_New_Bit_Field.ReadData
        OIT_CSDataServices_DID_0x1d01_Accelerator_pedal_sensor_1_voltage_ReadData_CSDataServices_DID_0x1d01_Accelerator_pedal_seFCFA0C2C: start-on-event=CSDataServices_DID_0x1d01_Accelerator_pedal_sensor_1_voltage_ReadData, operation=CSDataServices_DID_0x1d01_Accelerator_pedal_sensor_1_voltage.ReadData
        OIT_CSDataServices_DID_0xf1a4_Date_And_Time_Month_ReadData_CSDataServices_DID_0xf1a4_Date_And_Time_Month_ReadData: start-on-event=CSDataServices_DID_0xf1a4_Date_And_Time_Month_ReadData, operation=CSDataServices_DID_0xf1a4_Date_And_Time_Month.ReadData
        OIT_CSDataServices_DID_0x1d05_POD_OBC_InputACVoltage_ReadData_CSDataServices_DID_0x1d05_POD_OBC_InputACVoltage_ReadData: start-on-event=CSDataServices_DID_0x1d05_POD_OBC_InputACVoltage_ReadData, operation=CSDataServices_DID_0x1d05_POD_OBC_InputACVoltage.ReadData
        OIT_CSDataServices_DID_0xf1a6_SOC_ReadData_CSDataServices_DID_0xf1a6_SOC_ReadData: start-on-event=CSDataServices_DID_0xf1a6_SOC_ReadData, operation=CSDataServices_DID_0xf1a6_SOC.ReadData
        OIT_CSDataServices_DID_0xf1a0_Ignition_Switch_Signal_ReadData_CSDataServices_DID_0xf1a0_Ignition_Switch_Signal_ReadData: start-on-event=CSDataServices_DID_0xf1a0_Ignition_Switch_Signal_ReadData, operation=CSDataServices_DID_0xf1a0_Ignition_Switch_Signal.ReadData
        OIT_CSDataServices_DID_0xf1a7_Gear_ReadData_CSDataServices_DID_0xf1a7_Gear_ReadData: start-on-event=CSDataServices_DID_0xf1a7_Gear_ReadData, operation=CSDataServices_DID_0xf1a7_Gear.ReadData
        OIT_CSDataServices_DID_0x1d01_VCU_AccelerationPedal_ReadData_CSDataServices_DID_0x1d01_VCU_AccelerationPedal_ReadData: start-on-event=CSDataServices_DID_0x1d01_VCU_AccelerationPedal_ReadData, operation=CSDataServices_DID_0x1d01_VCU_AccelerationPedal.ReadData
        OIT_CSDataServices_DID_0x1d11_Mainrealy1_ReadData_CSDataServices_DID_0x1d11_Mainrealy1_ReadData: start-on-event=CSDataServices_DID_0x1d11_Mainrealy1_ReadData, operation=CSDataServices_DID_0x1d11_Mainrealy1.ReadData
        OIT_CSDataServices_DID_0xf1a4_Date_And_Time_Second_ReadData_CSDataServices_DID_0xf1a4_Date_And_Time_Second_ReadData: start-on-event=CSDataServices_DID_0xf1a4_Date_And_Time_Second_ReadData, operation=CSDataServices_DID_0xf1a4_Date_And_Time_Second.ReadData
        OIT_CSDataServices_DID_0xf1a4_Date_And_Time_Minute_ReadData_CSDataServices_DID_0xf1a4_Date_And_Time_Minute_ReadData: start-on-event=CSDataServices_DID_0xf1a4_Date_And_Time_Minute_ReadData, operation=CSDataServices_DID_0xf1a4_Date_And_Time_Minute.ReadData
        OIT_CSDataServices_DID_0x1d05_POD_OBC_OutputDCChargeVoltage_ReadData_CSDataServices_DID_0x1d05_POD_OBC_OutputDCChargeVol68FE7A1B: start-on-event=CSDataServices_DID_0x1d05_POD_OBC_OutputDCChargeVoltage_ReadData, operation=CSDataServices_DID_0x1d05_POD_OBC_OutputDCChargeVoltage.ReadData
        OIT_CSDataServices_DID_0xf1a1_Battery_Voltage_ReadData_CSDataServices_DID_0xf1a1_Battery_Voltage_ReadData: start-on-event=CSDataServices_DID_0xf1a1_Battery_Voltage_ReadData, operation=CSDataServices_DID_0xf1a1_Battery_Voltage.ReadData
        OIT_CSDataServices_DID_0xf1a2_Total_Odometer_ReadData_CSDataServices_DID_0xf1a2_Total_Odometer_ReadData: start-on-event=CSDataServices_DID_0xf1a2_Total_Odometer_ReadData, operation=CSDataServices_DID_0xf1a2_Total_Odometer.ReadData
        OIT_CSDataServices_DID_0xf1a3_Vehicle_speed_ReadData_CSDataServices_DID_0xf1a3_Vehicle_speed_ReadData: start-on-event=CSDataServices_DID_0xf1a3_Vehicle_speed_ReadData, operation=CSDataServices_DID_0xf1a3_Vehicle_speed.ReadData
        OIT_CSDataServices_DID_0x1d05_VCU_OBC_ChargeCurrentCommand_ReadData_CSDataServices_DID_0x1d05_VCU_OBC_ChargeCurrentCommaB2971C5F: start-on-event=CSDataServices_DID_0x1d05_VCU_OBC_ChargeCurrentCommand_ReadData, operation=CSDataServices_DID_0x1d05_VCU_OBC_ChargeCurrentCommand.ReadData
        OIT_CSDataServices_DID_0xf1a5_VCU_HVStatus_ReadData_CSDataServices_DID_0xf1a5_VCU_HVStatus_ReadData: start-on-event=CSDataServices_DID_0xf1a5_VCU_HVStatus_ReadData, operation=CSDataServices_DID_0xf1a5_VCU_HVStatus.ReadData
        OIT_CSDataServices_DID_0xf1a4_Date_And_Time_Hour_ReadData_CSDataServices_DID_0xf1a4_Date_And_Time_Hour_ReadData: start-on-event=CSDataServices_DID_0xf1a4_Date_And_Time_Hour_ReadData, operation=CSDataServices_DID_0xf1a4_Date_And_Time_Hour.ReadData
        OIT_CSDataServices_DID_0xf1a4_Date_And_Time_Day_ReadData_CSDataServices_DID_0xf1a4_Date_And_Time_Day_ReadData: start-on-event=CSDataServices_DID_0xf1a4_Date_And_Time_Day_ReadData, operation=CSDataServices_DID_0xf1a4_Date_And_Time_Day.ReadData
        OIT_DataServices_VCU_PowerMaxAllowed_parameter2_BMSDisChgPowerLimit_ConditionCheckRead_DataServices_VCU_PowerMaxAllowed_72ABAF31: start-on-event=DataServices_VCU_PowerMaxAllowed_parameter2_BMSDisChgPowerLimit_ConditionCheckRead, operation=DataServices_VCU_PowerMaxAllowed_parameter2_BMSDisChgPowerLimit.ConditionCheckRead
        OIT_DataServices_VCU_PowerMaxAllowed_parameter2_BMSDisChgPowerLimit_ReadData_DataServices_VCU_PowerMaxAllowed_parameter2416060E5: start-on-event=DataServices_VCU_PowerMaxAllowed_parameter2_BMSDisChgPowerLimit_ReadData, operation=DataServices_VCU_PowerMaxAllowed_parameter2_BMSDisChgPowerLimit.ReadData
        OIT_DataServices_AC_charging_parameter_POD_OBC_OutputDCChargeCurrent_ConditionCheckRead_DataServices_AC_charging_parametB0786408: start-on-event=DataServices_AC_charging_parameter_POD_OBC_OutputDCChargeCurrent_ConditionCheckRead, operation=DataServices_AC_charging_parameter_POD_OBC_OutputDCChargeCurrent.ConditionCheckRead
        OIT_DataServices_AC_charging_parameter_POD_OBC_OutputDCChargeCurrent_ReadData_DataServices_AC_charging_parameter_POD_OBC860C3036: start-on-event=DataServices_AC_charging_parameter_POD_OBC_OutputDCChargeCurrent_ReadData, operation=DataServices_AC_charging_parameter_POD_OBC_OutputDCChargeCurrent.ReadData
        OIT_DataServices_AC_charging_parameter_POD_OBC_OutputDCChargeVoltage_ConditionCheckRead_DataServices_AC_charging_paramet8422C59A: start-on-event=DataServices_AC_charging_parameter_POD_OBC_OutputDCChargeVoltage_ConditionCheckRead, operation=DataServices_AC_charging_parameter_POD_OBC_OutputDCChargeVoltage.ConditionCheckRead
        OIT_DataServices_AC_charging_parameter_POD_OBC_OutputDCChargeVoltage_ReadData_DataServices_AC_charging_parameter_POD_OBC68E618FF: start-on-event=DataServices_AC_charging_parameter_POD_OBC_OutputDCChargeVoltage_ReadData, operation=DataServices_AC_charging_parameter_POD_OBC_OutputDCChargeVoltage.ReadData
        OIT_DataServices_Date_And_Time_Date_And_Time_Hour_ConditionCheckRead_DataServices_Date_And_Time_Date_And_Time_Hour_CondiBB72C462: start-on-event=DataServices_Date_And_Time_Date_And_Time_Hour_ConditionCheckRead, operation=DataServices_Date_And_Time_Date_And_Time_Hour.ConditionCheckRead
        OIT_DataServices_Date_And_Time_Date_And_Time_Hour_ReadData_DataServices_Date_And_Time_Date_And_Time_Hour_ReadData: start-on-event=DataServices_Date_And_Time_Date_And_Time_Hour_ReadData, operation=DataServices_Date_And_Time_Date_And_Time_Hour.ReadData
        OIT_DataServices_DC_Charging_port_Temperature_POD_DCInletTempB_ConditionCheckRead_DataServices_DC_Charging_port_Temperat202CB73F: start-on-event=DataServices_DC_Charging_port_Temperature_POD_DCInletTempB_ConditionCheckRead, operation=DataServices_DC_Charging_port_Temperature_POD_DCInletTempB.ConditionCheckRead
        OIT_DataServices_DC_Charging_port_Temperature_POD_DCInletTempB_ReadData_DataServices_DC_Charging_port_Temperature_POD_DC232C0D51: start-on-event=DataServices_DC_Charging_port_Temperature_POD_DCInletTempB_ReadData, operation=DataServices_DC_Charging_port_Temperature_POD_DCInletTempB.ReadData
        OIT_DataServices_Driver_Mode_Driver_Mode_ConditionCheckRead_DataServices_Driver_Mode_Driver_Mode_ConditionCheckRead: start-on-event=DataServices_Driver_Mode_Driver_Mode_ConditionCheckRead, operation=DataServices_Driver_Mode_Driver_Mode.ConditionCheckRead
        OIT_DataServices_Driver_Mode_Driver_Mode_ReadData_DataServices_Driver_Mode_Driver_Mode_ReadData: start-on-event=DataServices_Driver_Mode_Driver_Mode_ReadData, operation=DataServices_Driver_Mode_Driver_Mode.ReadData
        OIT_DataServices_VCU_PowerMaxAllowed_parameter3_V2LPower_ConditionCheckRead_DataServices_VCU_PowerMaxAllowed_parameter3_D19436B1: start-on-event=DataServices_VCU_PowerMaxAllowed_parameter3_V2LPower_ConditionCheckRead, operation=DataServices_VCU_PowerMaxAllowed_parameter3_V2LPower.ConditionCheckRead
        OIT_DataServices_VCU_PowerMaxAllowed_parameter3_V2LPower_ReadData_DataServices_VCU_PowerMaxAllowed_parameter3_V2LPower_ReadData: start-on-event=DataServices_VCU_PowerMaxAllowed_parameter3_V2LPower_ReadData, operation=DataServices_VCU_PowerMaxAllowed_parameter3_V2LPower.ReadData
        OIT_DataServices_VCU_control_S2_status_New_Bit_Field_ConditionCheckRead_DataServices_VCU_control_S2_status_New_Bit_Field3163F5DE: start-on-event=DataServices_VCU_control_S2_status_New_Bit_Field_ConditionCheckRead, operation=DataServices_VCU_control_S2_status_New_Bit_Field.ConditionCheckRead
        OIT_DataServices_VCU_control_S2_status_New_Bit_Field_ReadData_DataServices_VCU_control_S2_status_New_Bit_Field_ReadData: start-on-event=DataServices_VCU_control_S2_status_New_Bit_Field_ReadData, operation=DataServices_VCU_control_S2_status_New_Bit_Field.ReadData
        OIT_DataServices_Gear_Gear_ConditionCheckRead_DataServices_Gear_Gear_ConditionCheckRead: start-on-event=DataServices_Gear_Gear_ConditionCheckRead, operation=DataServices_Gear_Gear.ConditionCheckRead
        OIT_DataServices_Gear_Gear_ReadData_DataServices_Gear_Gear_ReadData: start-on-event=DataServices_Gear_Gear_ReadData, operation=DataServices_Gear_Gear.ReadData
        OIT_DataServices_Date_And_Time_Date_And_Time_Month_ConditionCheckRead_DataServices_Date_And_Time_Date_And_Time_Month_ConA996611D: start-on-event=DataServices_Date_And_Time_Date_And_Time_Month_ConditionCheckRead, operation=DataServices_Date_And_Time_Date_And_Time_Month.ConditionCheckRead
        OIT_DataServices_Date_And_Time_Date_And_Time_Month_ReadData_DataServices_Date_And_Time_Date_And_Time_Month_ReadData: start-on-event=DataServices_Date_And_Time_Date_And_Time_Month_ReadData, operation=DataServices_Date_And_Time_Date_And_Time_Month.ReadData
        OIT_DataServices_Read_Write_coding_data_string_CDS_CDS_Short_VIN_High_Byte_0_WriteData_DataServices_Read_Write_coding_da53C610BD: start-on-event=DataServices_Read_Write_coding_data_string_CDS_CDS_Short_VIN_High_Byte_0_WriteData, operation=DataServices_Read_Write_coding_data_string_CDS_CDS_Short_VIN_High_Byte_0.WriteData
        OIT_DataServices_Read_Write_coding_data_string_CDS_CDS_Short_VIN_High_Byte_0_ConditionCheckRead_DataServices_Read_Write_3F3653A7: start-on-event=DataServices_Read_Write_coding_data_string_CDS_CDS_Short_VIN_High_Byte_0_ConditionCheckRead, operation=DataServices_Read_Write_coding_data_string_CDS_CDS_Short_VIN_High_Byte_0.ConditionCheckRead
        OIT_DataServices_Read_Write_coding_data_string_CDS_CDS_Short_VIN_High_Byte_0_ReadData_DataServices_Read_Write_coding_dat8A86F912: start-on-event=DataServices_Read_Write_coding_data_string_CDS_CDS_Short_VIN_High_Byte_0_ReadData, operation=DataServices_Read_Write_coding_data_string_CDS_CDS_Short_VIN_High_Byte_0.ReadData
        OIT_DataServices_HV_part_work_mode_HV_part_work_mode1_ConditionCheckRead_DataServices_HV_part_work_mode_HV_part_work_mod7774CD53: start-on-event=DataServices_HV_part_work_mode_HV_part_work_mode1_ConditionCheckRead, operation=DataServices_HV_part_work_mode_HV_part_work_mode1.ConditionCheckRead
        OIT_DataServices_HV_part_work_mode_HV_part_work_mode1_ReadData_DataServices_HV_part_work_mode_HV_part_work_mode1_ReadData: start-on-event=DataServices_HV_part_work_mode_HV_part_work_mode1_ReadData, operation=DataServices_HV_part_work_mode_HV_part_work_mode1.ReadData
        OIT_DataServices_ECU_application_software_ASW_version_number_Major_release_ConditionCheckRead_DataServices_ECU_applicatiF1E2897A: start-on-event=DataServices_ECU_application_software_ASW_version_number_Major_release_ConditionCheckRead, operation=DataServices_ECU_application_software_ASW_version_number_Major_release.ConditionCheckRead
        OIT_DataServices_ECU_application_software_ASW_version_number_Major_release_ReadData_DataServices_ECU_application_softwar1113C06A: start-on-event=DataServices_ECU_application_software_ASW_version_number_Major_release_ReadData, operation=DataServices_ECU_application_software_ASW_version_number_Major_release.ReadData
        OIT_DataServices_PWT_vehicle_fault_PWT_ErrorLevel2_ConditionCheckRead_DataServices_PWT_vehicle_fault_PWT_ErrorLevel2_ConB1DC5DA2: start-on-event=DataServices_PWT_vehicle_fault_PWT_ErrorLevel2_ConditionCheckRead, operation=DataServices_PWT_vehicle_fault_PWT_ErrorLevel2.ConditionCheckRead
        OIT_DataServices_PWT_vehicle_fault_PWT_ErrorLevel2_ReadData_DataServices_PWT_vehicle_fault_PWT_ErrorLevel2_ReadData: start-on-event=DataServices_PWT_vehicle_fault_PWT_ErrorLevel2_ReadData, operation=DataServices_PWT_vehicle_fault_PWT_ErrorLevel2.ReadData
        OIT_DataServices_VCU_PowerMaxAllowed_parameter2_BMSChgPowerLimit_ConditionCheckRead_DataServices_VCU_PowerMaxAllowed_par1B358520: start-on-event=DataServices_VCU_PowerMaxAllowed_parameter2_BMSChgPowerLimit_ConditionCheckRead, operation=DataServices_VCU_PowerMaxAllowed_parameter2_BMSChgPowerLimit.ConditionCheckRead
        OIT_DataServices_VCU_PowerMaxAllowed_parameter2_BMSChgPowerLimit_ReadData_DataServices_VCU_PowerMaxAllowed_parameter2_BM5B4B7F30: start-on-event=DataServices_VCU_PowerMaxAllowed_parameter2_BMSChgPowerLimit_ReadData, operation=DataServices_VCU_PowerMaxAllowed_parameter2_BMSChgPowerLimit.ReadData
        OIT_DataServices_Read_Write_coding_data_string_CDS_Configuration_WriteData_DataServices_Read_Write_coding_data_string_CDAD31AD2D: start-on-event=DataServices_Read_Write_coding_data_string_CDS_Configuration_WriteData, operation=DataServices_Read_Write_coding_data_string_CDS_Configuration.WriteData
        OIT_DataServices_Read_Write_coding_data_string_CDS_Configuration_ConditionCheckRead_DataServices_Read_Write_coding_data_A7028151: start-on-event=DataServices_Read_Write_coding_data_string_CDS_Configuration_ConditionCheckRead, operation=DataServices_Read_Write_coding_data_string_CDS_Configuration.ConditionCheckRead
        OIT_DataServices_Read_Write_coding_data_string_CDS_Configuration_ReadData_DataServices_Read_Write_coding_data_string_CDS3EE43298: start-on-event=DataServices_Read_Write_coding_data_string_CDS_Configuration_ReadData, operation=DataServices_Read_Write_coding_data_string_CDS_Configuration.ReadData
        OIT_DataServices_VCU_HVStatus_VCU_HVStatus_ConditionCheckRead_DataServices_VCU_HVStatus_VCU_HVStatus_ConditionCheckRead: start-on-event=DataServices_VCU_HVStatus_VCU_HVStatus_ConditionCheckRead, operation=DataServices_VCU_HVStatus_VCU_HVStatus.ConditionCheckRead
        OIT_DataServices_VCU_HVStatus_VCU_HVStatus_ReadData_DataServices_VCU_HVStatus_VCU_HVStatus_ReadData: start-on-event=DataServices_VCU_HVStatus_VCU_HVStatus_ReadData, operation=DataServices_VCU_HVStatus_VCU_HVStatus.ReadData
        OIT_DataServices_Battery_Voltage_Battery_Voltage_ConditionCheckRead_DataServices_Battery_Voltage_Battery_Voltage_Conditi54DCDF79: start-on-event=DataServices_Battery_Voltage_Battery_Voltage_ConditionCheckRead, operation=DataServices_Battery_Voltage_Battery_Voltage.ConditionCheckRead
        OIT_DataServices_Battery_Voltage_Battery_Voltage_ReadData_DataServices_Battery_Voltage_Battery_Voltage_ReadData: start-on-event=DataServices_Battery_Voltage_Battery_Voltage_ReadData, operation=DataServices_Battery_Voltage_Battery_Voltage.ReadData
        OIT_DataServices_SOC_SOC_ConditionCheckRead_DataServices_SOC_SOC_ConditionCheckRead: start-on-event=DataServices_SOC_SOC_ConditionCheckRead, operation=DataServices_SOC_SOC.ConditionCheckRead
        OIT_DataServices_SOC_SOC_ReadData_DataServices_SOC_SOC_ReadData: start-on-event=DataServices_SOC_SOC_ReadData, operation=DataServices_SOC_SOC.ReadData
        OIT_DataServices_VCU_PowerMaxAllowed_parameter1_VCU_TCUPowerAllowed_ConditionCheckRead_DataServices_VCU_PowerMaxAllowed_D1A397BF: start-on-event=DataServices_VCU_PowerMaxAllowed_parameter1_VCU_TCUPowerAllowed_ConditionCheckRead, operation=DataServices_VCU_PowerMaxAllowed_parameter1_VCU_TCUPowerAllowed.ConditionCheckRead
        OIT_DataServices_VCU_PowerMaxAllowed_parameter1_VCU_TCUPowerAllowed_ReadData_DataServices_VCU_PowerMaxAllowed_parameter11616B58E: start-on-event=DataServices_VCU_PowerMaxAllowed_parameter1_VCU_TCUPowerAllowed_ReadData, operation=DataServices_VCU_PowerMaxAllowed_parameter1_VCU_TCUPowerAllowed.ReadData
        OIT_DataServices_Read_Write_coding_data_string_CDS_Reserved3_WriteData_DataServices_Read_Write_coding_data_string_CDS_Re98885EF7: start-on-event=DataServices_Read_Write_coding_data_string_CDS_Reserved3_WriteData, operation=DataServices_Read_Write_coding_data_string_CDS_Reserved3.WriteData
        OIT_DataServices_Read_Write_coding_data_string_CDS_Reserved3_ConditionCheckRead_DataServices_Read_Write_coding_data_stri1B0885BB: start-on-event=DataServices_Read_Write_coding_data_string_CDS_Reserved3_ConditionCheckRead, operation=DataServices_Read_Write_coding_data_string_CDS_Reserved3.ConditionCheckRead
        OIT_DataServices_Read_Write_coding_data_string_CDS_Reserved3_ReadData_DataServices_Read_Write_coding_data_string_CDS_Res3B7A1818: start-on-event=DataServices_Read_Write_coding_data_string_CDS_Reserved3_ReadData, operation=DataServices_Read_Write_coding_data_string_CDS_Reserved3.ReadData
        OIT_DataServices_VCU_Torque_parameter_VCU_RegenTorqueCap_ConditionCheckRead_DataServices_VCU_Torque_parameter_VCU_RegenTC7E76AD6: start-on-event=DataServices_VCU_Torque_parameter_VCU_RegenTorqueCap_ConditionCheckRead, operation=DataServices_VCU_Torque_parameter_VCU_RegenTorqueCap.ConditionCheckRead
        OIT_DataServices_VCU_Torque_parameter_VCU_RegenTorqueCap_ReadData_DataServices_VCU_Torque_parameter_VCU_RegenTorqueCap_ReadData: start-on-event=DataServices_VCU_Torque_parameter_VCU_RegenTorqueCap_ReadData, operation=DataServices_VCU_Torque_parameter_VCU_RegenTorqueCap.ReadData
        OIT_DataServices_AC_charging_parameter_VCU_OBC_ChargeCurrentCommand_ConditionCheckRead_DataServices_AC_charging_parameteF5D0B23A: start-on-event=DataServices_AC_charging_parameter_VCU_OBC_ChargeCurrentCommand_ConditionCheckRead, operation=DataServices_AC_charging_parameter_VCU_OBC_ChargeCurrentCommand.ConditionCheckRead
        OIT_DataServices_AC_charging_parameter_VCU_OBC_ChargeCurrentCommand_ReadData_DataServices_AC_charging_parameter_VCU_OBC_F8749414: start-on-event=DataServices_AC_charging_parameter_VCU_OBC_ChargeCurrentCommand_ReadData, operation=DataServices_AC_charging_parameter_VCU_OBC_ChargeCurrentCommand.ReadData
        OIT_DataServices_DC_Charging_port_Temperature_POD_DCInletTempA_ConditionCheckRead_DataServices_DC_Charging_port_Temperat30CB450C: start-on-event=DataServices_DC_Charging_port_Temperature_POD_DCInletTempA_ConditionCheckRead, operation=DataServices_DC_Charging_port_Temperature_POD_DCInletTempA.ConditionCheckRead
        OIT_DataServices_DC_Charging_port_Temperature_POD_DCInletTempA_ReadData_DataServices_DC_Charging_port_Temperature_POD_DC158F8A7C: start-on-event=DataServices_DC_Charging_port_Temperature_POD_DCInletTempA_ReadData, operation=DataServices_DC_Charging_port_Temperature_POD_DCInletTempA.ReadData
        OIT_DataServices_Read_Write_coding_data_string_CDS_CDS_CRC_WriteData_DataServices_Read_Write_coding_data_string_CDS_CDS_97A6CE02: start-on-event=DataServices_Read_Write_coding_data_string_CDS_CDS_CRC_WriteData, operation=DataServices_Read_Write_coding_data_string_CDS_CDS_CRC.WriteData
        OIT_DataServices_Read_Write_coding_data_string_CDS_CDS_CRC_ConditionCheckRead_DataServices_Read_Write_coding_data_stringBE744EA6: start-on-event=DataServices_Read_Write_coding_data_string_CDS_CDS_CRC_ConditionCheckRead, operation=DataServices_Read_Write_coding_data_string_CDS_CDS_CRC.ConditionCheckRead
        OIT_DataServices_Read_Write_coding_data_string_CDS_CDS_CRC_ReadData_DataServices_Read_Write_coding_data_string_CDS_CDS_CF997A722: start-on-event=DataServices_Read_Write_coding_data_string_CDS_CDS_CRC_ReadData, operation=DataServices_Read_Write_coding_data_string_CDS_CDS_CRC.ReadData
        OIT_DataServices_Chargestatus_Chargestatus_ConditionCheckRead_DataServices_Chargestatus_Chargestatus_ConditionCheckRead: start-on-event=DataServices_Chargestatus_Chargestatus_ConditionCheckRead, operation=DataServices_Chargestatus_Chargestatus.ConditionCheckRead
        OIT_DataServices_Chargestatus_Chargestatus_ReadData_DataServices_Chargestatus_Chargestatus_ReadData: start-on-event=DataServices_Chargestatus_Chargestatus_ReadData, operation=DataServices_Chargestatus_Chargestatus.ReadData
        OIT_DataServices_Date_And_Time_Date_And_Time_Second_ConditionCheckRead_DataServices_Date_And_Time_Date_And_Time_Second_C830BED3A: start-on-event=DataServices_Date_And_Time_Date_And_Time_Second_ConditionCheckRead, operation=DataServices_Date_And_Time_Date_And_Time_Second.ConditionCheckRead
        OIT_DataServices_Date_And_Time_Date_And_Time_Second_ReadData_DataServices_Date_And_Time_Date_And_Time_Second_ReadData: start-on-event=DataServices_Date_And_Time_Date_And_Time_Second_ReadData, operation=DataServices_Date_And_Time_Date_And_Time_Second.ReadData
        OIT_DataServices_Date_And_Time_Date_And_Time_Year_ConditionCheckRead_DataServices_Date_And_Time_Date_And_Time_Year_Condi31C2CB6A: start-on-event=DataServices_Date_And_Time_Date_And_Time_Year_ConditionCheckRead, operation=DataServices_Date_And_Time_Date_And_Time_Year.ConditionCheckRead
        OIT_DataServices_Date_And_Time_Date_And_Time_Year_ReadData_DataServices_Date_And_Time_Date_And_Time_Year_ReadData: start-on-event=DataServices_Date_And_Time_Date_And_Time_Year_ReadData, operation=DataServices_Date_And_Time_Date_And_Time_Year.ReadData
        OIT_DataServices_Read_Write_coding_data_string_CDS_CDS_Short_VIN_High_Byte_3_WriteData_DataServices_Read_Write_coding_da666ADDD2: start-on-event=DataServices_Read_Write_coding_data_string_CDS_CDS_Short_VIN_High_Byte_3_WriteData, operation=DataServices_Read_Write_coding_data_string_CDS_CDS_Short_VIN_High_Byte_3.WriteData
        OIT_DataServices_Read_Write_coding_data_string_CDS_CDS_Short_VIN_High_Byte_3_ConditionCheckRead_DataServices_Read_Write_C2974E2C: start-on-event=DataServices_Read_Write_coding_data_string_CDS_CDS_Short_VIN_High_Byte_3_ConditionCheckRead, operation=DataServices_Read_Write_coding_data_string_CDS_CDS_Short_VIN_High_Byte_3.ConditionCheckRead
        OIT_DataServices_Read_Write_coding_data_string_CDS_CDS_Short_VIN_High_Byte_3_ReadData_DataServices_Read_Write_coding_dat519F2742: start-on-event=DataServices_Read_Write_coding_data_string_CDS_CDS_Short_VIN_High_Byte_3_ReadData, operation=DataServices_Read_Write_coding_data_string_CDS_CDS_Short_VIN_High_Byte_3.ReadData
        OIT_DataServices_VCU_Torque_parameter_Torque_MinAllowed_ConditionCheckRead_DataServices_VCU_Torque_parameter_Torque_MinA9F2E427C: start-on-event=DataServices_VCU_Torque_parameter_Torque_MinAllowed_ConditionCheckRead, operation=DataServices_VCU_Torque_parameter_Torque_MinAllowed.ConditionCheckRead
        OIT_DataServices_VCU_Torque_parameter_Torque_MinAllowed_ReadData_DataServices_VCU_Torque_parameter_Torque_MinAllowed_ReadData: start-on-event=DataServices_VCU_Torque_parameter_Torque_MinAllowed_ReadData, operation=DataServices_VCU_Torque_parameter_Torque_MinAllowed.ReadData
        OIT_DataServices_HV_part_work_mode_HV_part_work_mode2_ConditionCheckRead_DataServices_HV_part_work_mode_HV_part_work_mod74993601: start-on-event=DataServices_HV_part_work_mode_HV_part_work_mode2_ConditionCheckRead, operation=DataServices_HV_part_work_mode_HV_part_work_mode2.ConditionCheckRead
        OIT_DataServices_HV_part_work_mode_HV_part_work_mode2_ReadData_DataServices_HV_part_work_mode_HV_part_work_mode2_ReadData: start-on-event=DataServices_HV_part_work_mode_HV_part_work_mode2_ReadData, operation=DataServices_HV_part_work_mode_HV_part_work_mode2.ReadData
        OIT_DataServices_Read_Write_coding_data_string_CDS_CDS_Format_Byte_High_Byte_0_WriteData_DataServices_Read_Write_coding_FBE38F29: start-on-event=DataServices_Read_Write_coding_data_string_CDS_CDS_Format_Byte_High_Byte_0_WriteData, operation=DataServices_Read_Write_coding_data_string_CDS_CDS_Format_Byte_High_Byte_0.WriteData
        OIT_DataServices_Read_Write_coding_data_string_CDS_CDS_Format_Byte_High_Byte_0_ConditionCheckRead_DataServices_Read_WritB0D776FC: start-on-event=DataServices_Read_Write_coding_data_string_CDS_CDS_Format_Byte_High_Byte_0_ConditionCheckRead, operation=DataServices_Read_Write_coding_data_string_CDS_CDS_Format_Byte_High_Byte_0.ConditionCheckRead
        OIT_DataServices_Read_Write_coding_data_string_CDS_CDS_Format_Byte_High_Byte_0_ReadData_DataServices_Read_Write_coding_d68464FBD: start-on-event=DataServices_Read_Write_coding_data_string_CDS_CDS_Format_Byte_High_Byte_0_ReadData, operation=DataServices_Read_Write_coding_data_string_CDS_CDS_Format_Byte_High_Byte_0.ReadData
        OIT_DataServices_Date_And_Time_Date_And_Time_Minute_ConditionCheckRead_DataServices_Date_And_Time_Date_And_Time_Minute_CFF645055: start-on-event=DataServices_Date_And_Time_Date_And_Time_Minute_ConditionCheckRead, operation=DataServices_Date_And_Time_Date_And_Time_Minute.ConditionCheckRead
        OIT_DataServices_Date_And_Time_Date_And_Time_Minute_ReadData_DataServices_Date_And_Time_Date_And_Time_Minute_ReadData: start-on-event=DataServices_Date_And_Time_Date_And_Time_Minute_ReadData, operation=DataServices_Date_And_Time_Date_And_Time_Minute.ReadData
        OIT_DataServices_Date_And_Time_Date_And_Time_Day_ConditionCheckRead_DataServices_Date_And_Time_Date_And_Time_Day_Conditi78207D9F: start-on-event=DataServices_Date_And_Time_Date_And_Time_Day_ConditionCheckRead, operation=DataServices_Date_And_Time_Date_And_Time_Day.ConditionCheckRead
        OIT_DataServices_Date_And_Time_Date_And_Time_Day_ReadData_DataServices_Date_And_Time_Date_And_Time_Day_ReadData: start-on-event=DataServices_Date_And_Time_Date_And_Time_Day_ReadData, operation=DataServices_Date_And_Time_Date_And_Time_Day.ReadData
        OIT_DataServices_Read_Write_coding_data_string_CDS_Version_Byte_1_WriteData_DataServices_Read_Write_coding_data_string_CC3774674: start-on-event=DataServices_Read_Write_coding_data_string_CDS_Version_Byte_1_WriteData, operation=DataServices_Read_Write_coding_data_string_CDS_Version_Byte_1.WriteData
        OIT_DataServices_Read_Write_coding_data_string_CDS_Version_Byte_1_ConditionCheckRead_DataServices_Read_Write_coding_dataF4BFC475: start-on-event=DataServices_Read_Write_coding_data_string_CDS_Version_Byte_1_ConditionCheckRead, operation=DataServices_Read_Write_coding_data_string_CDS_Version_Byte_1.ConditionCheckRead
        OIT_DataServices_Read_Write_coding_data_string_CDS_Version_Byte_1_ReadData_DataServices_Read_Write_coding_data_string_CD9FCA3E92: start-on-event=DataServices_Read_Write_coding_data_string_CDS_Version_Byte_1_ReadData, operation=DataServices_Read_Write_coding_data_string_CDS_Version_Byte_1.ReadData
        OIT_DataServices_VCU_PowerMaxAllowed_parameter1_VCU_DisChgPowerLimit_ConditionCheckRead_DataServices_VCU_PowerMaxAllowed779FD80D: start-on-event=DataServices_VCU_PowerMaxAllowed_parameter1_VCU_DisChgPowerLimit_ConditionCheckRead, operation=DataServices_VCU_PowerMaxAllowed_parameter1_VCU_DisChgPowerLimit.ConditionCheckRead
        OIT_DataServices_VCU_PowerMaxAllowed_parameter1_VCU_DisChgPowerLimit_ReadData_DataServices_VCU_PowerMaxAllowed_parameterDA2DE856: start-on-event=DataServices_VCU_PowerMaxAllowed_parameter1_VCU_DisChgPowerLimit_ReadData, operation=DataServices_VCU_PowerMaxAllowed_parameter1_VCU_DisChgPowerLimit.ReadData
        OIT_DataServices_VCU_Torque_parameter_VCU_MCUDesiredTorque_ConditionCheckRead_DataServices_VCU_Torque_parameter_VCU_MCUDFF4B2CB6: start-on-event=DataServices_VCU_Torque_parameter_VCU_MCUDesiredTorque_ConditionCheckRead, operation=DataServices_VCU_Torque_parameter_VCU_MCUDesiredTorque.ConditionCheckRead
        OIT_DataServices_VCU_Torque_parameter_VCU_MCUDesiredTorque_ReadData_DataServices_VCU_Torque_parameter_VCU_MCUDesiredTorq8B831474: start-on-event=DataServices_VCU_Torque_parameter_VCU_MCUDesiredTorque_ReadData, operation=DataServices_VCU_Torque_parameter_VCU_MCUDesiredTorque.ReadData
        OIT_DataServices_AC_charging_parameter_POD_OBC_InputACVoltage_ConditionCheckRead_DataServices_AC_charging_parameter_POD_FFA58DA5: start-on-event=DataServices_AC_charging_parameter_POD_OBC_InputACVoltage_ConditionCheckRead, operation=DataServices_AC_charging_parameter_POD_OBC_InputACVoltage.ConditionCheckRead
        OIT_DataServices_AC_charging_parameter_POD_OBC_InputACVoltage_ReadData_DataServices_AC_charging_parameter_POD_OBC_InputAAA558E37: start-on-event=DataServices_AC_charging_parameter_POD_OBC_InputACVoltage_ReadData, operation=DataServices_AC_charging_parameter_POD_OBC_InputACVoltage.ReadData
        OIT_DataServices_VCU_AccPealparameter_VCU_AccelerationPedal_ConditionCheckRead_DataServices_VCU_AccPealparameter_VCU_Acc2B2E9F39: start-on-event=DataServices_VCU_AccPealparameter_VCU_AccelerationPedal_ConditionCheckRead, operation=DataServices_VCU_AccPealparameter_VCU_AccelerationPedal.ConditionCheckRead
        OIT_DataServices_VCU_AccPealparameter_VCU_AccelerationPedal_ReadData_DataServices_VCU_AccPealparameter_VCU_AccelerationP2333F833: start-on-event=DataServices_VCU_AccPealparameter_VCU_AccelerationPedal_ReadData, operation=DataServices_VCU_AccPealparameter_VCU_AccelerationPedal.ReadData
        OIT_DataServices_VCU_Torque_parameter_Torque_MaxAllowed_ConditionCheckRead_DataServices_VCU_Torque_parameter_Torque_MaxA09407894: start-on-event=DataServices_VCU_Torque_parameter_Torque_MaxAllowed_ConditionCheckRead, operation=DataServices_VCU_Torque_parameter_Torque_MaxAllowed.ConditionCheckRead
        OIT_DataServices_VCU_Torque_parameter_Torque_MaxAllowed_ReadData_DataServices_VCU_Torque_parameter_Torque_MaxAllowed_ReadData: start-on-event=DataServices_VCU_Torque_parameter_Torque_MaxAllowed_ReadData, operation=DataServices_VCU_Torque_parameter_Torque_MaxAllowed.ReadData
        OIT_DataServices_Read_Write_coding_data_string_CDS_Version_Byte_0_WriteData_DataServices_Read_Write_coding_data_string_C04864D4A: start-on-event=DataServices_Read_Write_coding_data_string_CDS_Version_Byte_0_WriteData, operation=DataServices_Read_Write_coding_data_string_CDS_Version_Byte_0.WriteData
        OIT_DataServices_Read_Write_coding_data_string_CDS_Version_Byte_0_ConditionCheckRead_DataServices_Read_Write_coding_data1F138F0C: start-on-event=DataServices_Read_Write_coding_data_string_CDS_Version_Byte_0_ConditionCheckRead, operation=DataServices_Read_Write_coding_data_string_CDS_Version_Byte_0.ConditionCheckRead
        OIT_DataServices_Read_Write_coding_data_string_CDS_Version_Byte_0_ReadData_DataServices_Read_Write_coding_data_string_CD1DC996DF: start-on-event=DataServices_Read_Write_coding_data_string_CDS_Version_Byte_0_ReadData, operation=DataServices_Read_Write_coding_data_string_CDS_Version_Byte_0.ReadData
        OIT_DataServices_VCU_HV_InterLock_PWM_pfrequency_VCU_HVIL_ConditionCheckRead_DataServices_VCU_HV_InterLock_PWM_pfrequencCF866B72: start-on-event=DataServices_VCU_HV_InterLock_PWM_pfrequency_VCU_HVIL_ConditionCheckRead, operation=DataServices_VCU_HV_InterLock_PWM_pfrequency_VCU_HVIL.ConditionCheckRead
        OIT_DataServices_VCU_HV_InterLock_PWM_pfrequency_VCU_HVIL_ReadData_DataServices_VCU_HV_InterLock_PWM_pfrequency_VCU_HVIL7A0CF63D: start-on-event=DataServices_VCU_HV_InterLock_PWM_pfrequency_VCU_HVIL_ReadData, operation=DataServices_VCU_HV_InterLock_PWM_pfrequency_VCU_HVIL.ReadData
        OIT_DataServices_Total_Odometer_Total_Odometer_ConditionCheckRead_DataServices_Total_Odometer_Total_Odometer_ConditionCheckRead: start-on-event=DataServices_Total_Odometer_Total_Odometer_ConditionCheckRead, operation=DataServices_Total_Odometer_Total_Odometer.ConditionCheckRead
        OIT_DataServices_Total_Odometer_Total_Odometer_ReadData_DataServices_Total_Odometer_Total_Odometer_ReadData: start-on-event=DataServices_Total_Odometer_Total_Odometer_ReadData, operation=DataServices_Total_Odometer_Total_Odometer.ReadData
        OIT_DataServices_VCU_AccPealparameter_VCU_VehicleSpeed_ConditionCheckRead_DataServices_VCU_AccPealparameter_VCU_VehicleSD3CC934E: start-on-event=DataServices_VCU_AccPealparameter_VCU_VehicleSpeed_ConditionCheckRead, operation=DataServices_VCU_AccPealparameter_VCU_VehicleSpeed.ConditionCheckRead
        OIT_DataServices_VCU_AccPealparameter_VCU_VehicleSpeed_ReadData_DataServices_VCU_AccPealparameter_VCU_VehicleSpeed_ReadData: start-on-event=DataServices_VCU_AccPealparameter_VCU_VehicleSpeed_ReadData, operation=DataServices_VCU_AccPealparameter_VCU_VehicleSpeed.ReadData
        OIT_DataServices_VCU_AccPealparameter_Accelerator_pedal_sensor_1_voltage_ConditionCheckRead_DataServices_VCU_AccPealpara04216D66: start-on-event=DataServices_VCU_AccPealparameter_Accelerator_pedal_sensor_1_voltage_ConditionCheckRead, operation=DataServices_VCU_AccPealparameter_Accelerator_pedal_sensor_1_voltage.ConditionCheckRead
        OIT_DataServices_VCU_AccPealparameter_Accelerator_pedal_sensor_1_voltage_ReadData_DataServices_VCU_AccPealparameter_AcceC38CC5E5: start-on-event=DataServices_VCU_AccPealparameter_Accelerator_pedal_sensor_1_voltage_ReadData, operation=DataServices_VCU_AccPealparameter_Accelerator_pedal_sensor_1_voltage.ReadData
        OIT_DataServices_Read_Write_coding_data_string_CDS_Reserved2_WriteData_DataServices_Read_Write_coding_data_string_CDS_ReA4A59712: start-on-event=DataServices_Read_Write_coding_data_string_CDS_Reserved2_WriteData, operation=DataServices_Read_Write_coding_data_string_CDS_Reserved2.WriteData
        OIT_DataServices_Read_Write_coding_data_string_CDS_Reserved2_ConditionCheckRead_DataServices_Read_Write_coding_data_striA169333F: start-on-event=DataServices_Read_Write_coding_data_string_CDS_Reserved2_ConditionCheckRead, operation=DataServices_Read_Write_coding_data_string_CDS_Reserved2.ConditionCheckRead
        OIT_DataServices_Read_Write_coding_data_string_CDS_Reserved2_ReadData_DataServices_Read_Write_coding_data_string_CDS_Res5AFAC218: start-on-event=DataServices_Read_Write_coding_data_string_CDS_Reserved2_ReadData, operation=DataServices_Read_Write_coding_data_string_CDS_Reserved2.ReadData
        OIT_DataServices_VCU_control_main_relay_Mainrealy1_ConditionCheckRead_DataServices_VCU_control_main_relay_Mainrealy1_Con2B1D65F5: start-on-event=DataServices_VCU_control_main_relay_Mainrealy1_ConditionCheckRead, operation=DataServices_VCU_control_main_relay_Mainrealy1.ConditionCheckRead
        OIT_DataServices_VCU_control_main_relay_Mainrealy1_ReadData_DataServices_VCU_control_main_relay_Mainrealy1_ReadData: start-on-event=DataServices_VCU_control_main_relay_Mainrealy1_ReadData, operation=DataServices_VCU_control_main_relay_Mainrealy1.ReadData
        OIT_DataServices_PWT_vehicle_fault_PWT_ErrorLevel1_ConditionCheckRead_DataServices_PWT_vehicle_fault_PWT_ErrorLevel1_Con6AD84097: start-on-event=DataServices_PWT_vehicle_fault_PWT_ErrorLevel1_ConditionCheckRead, operation=DataServices_PWT_vehicle_fault_PWT_ErrorLevel1.ConditionCheckRead
        OIT_DataServices_PWT_vehicle_fault_PWT_ErrorLevel1_ReadData_DataServices_PWT_vehicle_fault_PWT_ErrorLevel1_ReadData: start-on-event=DataServices_PWT_vehicle_fault_PWT_ErrorLevel1_ReadData, operation=DataServices_PWT_vehicle_fault_PWT_ErrorLevel1.ReadData
        OIT_DataServices_Read_Write_coding_data_string_CDS_CDS_Short_VIN_High_Byte_4_WriteData_DataServices_Read_Write_coding_daA887FE16: start-on-event=DataServices_Read_Write_coding_data_string_CDS_CDS_Short_VIN_High_Byte_4_WriteData, operation=DataServices_Read_Write_coding_data_string_CDS_CDS_Short_VIN_High_Byte_4.WriteData
        OIT_DataServices_Read_Write_coding_data_string_CDS_CDS_Short_VIN_High_Byte_4_ConditionCheckRead_DataServices_Read_Write_B63B7802: start-on-event=DataServices_Read_Write_coding_data_string_CDS_CDS_Short_VIN_High_Byte_4_ConditionCheckRead, operation=DataServices_Read_Write_coding_data_string_CDS_CDS_Short_VIN_High_Byte_4.ConditionCheckRead
        OIT_DataServices_Read_Write_coding_data_string_CDS_CDS_Short_VIN_High_Byte_4_ReadData_DataServices_Read_Write_coding_datC305D5AC: start-on-event=DataServices_Read_Write_coding_data_string_CDS_CDS_Short_VIN_High_Byte_4_ReadData, operation=DataServices_Read_Write_coding_data_string_CDS_CDS_Short_VIN_High_Byte_4.ReadData
        OIT_DataServices_VCU_AccPealparameter_Accelerator_pedal_sensor_2_voltage_ConditionCheckRead_DataServices_VCU_AccPealpara0457C179: start-on-event=DataServices_VCU_AccPealparameter_Accelerator_pedal_sensor_2_voltage_ConditionCheckRead, operation=DataServices_VCU_AccPealparameter_Accelerator_pedal_sensor_2_voltage.ConditionCheckRead
        OIT_DataServices_VCU_AccPealparameter_Accelerator_pedal_sensor_2_voltage_ReadData_DataServices_VCU_AccPealparameter_Acce93708880: start-on-event=DataServices_VCU_AccPealparameter_Accelerator_pedal_sensor_2_voltage_ReadData, operation=DataServices_VCU_AccPealparameter_Accelerator_pedal_sensor_2_voltage.ReadData
        OIT_DataServices_ECU_application_software_ASW_version_number_Minor_release_ConditionCheckRead_DataServices_ECU_applicati54A50D51: start-on-event=DataServices_ECU_application_software_ASW_version_number_Minor_release_ConditionCheckRead, operation=DataServices_ECU_application_software_ASW_version_number_Minor_release.ConditionCheckRead
        OIT_DataServices_ECU_application_software_ASW_version_number_Minor_release_ReadData_DataServices_ECU_application_softwarDA7FAA0E: start-on-event=DataServices_ECU_application_software_ASW_version_number_Minor_release_ReadData, operation=DataServices_ECU_application_software_ASW_version_number_Minor_release.ReadData
        OIT_DataServices_Read_Write_coding_data_string_CDS_CDS_Format_Byte_High_Byte_1_WriteData_DataServices_Read_Write_coding_E56BDD2B: start-on-event=DataServices_Read_Write_coding_data_string_CDS_CDS_Format_Byte_High_Byte_1_WriteData, operation=DataServices_Read_Write_coding_data_string_CDS_CDS_Format_Byte_High_Byte_1.WriteData
        OIT_DataServices_Read_Write_coding_data_string_CDS_CDS_Format_Byte_High_Byte_1_ConditionCheckRead_DataServices_Read_WritABB766D2: start-on-event=DataServices_Read_Write_coding_data_string_CDS_CDS_Format_Byte_High_Byte_1_ConditionCheckRead, operation=DataServices_Read_Write_coding_data_string_CDS_CDS_Format_Byte_High_Byte_1.ConditionCheckRead
        OIT_DataServices_Read_Write_coding_data_string_CDS_CDS_Format_Byte_High_Byte_1_ReadData_DataServices_Read_Write_coding_dE3BE4259: start-on-event=DataServices_Read_Write_coding_data_string_CDS_CDS_Format_Byte_High_Byte_1_ReadData, operation=DataServices_Read_Write_coding_data_string_CDS_CDS_Format_Byte_High_Byte_1.ReadData
        OIT_DataServices_Vehicle_speed_Vehicle_speed_ConditionCheckRead_DataServices_Vehicle_speed_Vehicle_speed_ConditionCheckRead: start-on-event=DataServices_Vehicle_speed_Vehicle_speed_ConditionCheckRead, operation=DataServices_Vehicle_speed_Vehicle_speed.ConditionCheckRead
        OIT_DataServices_Vehicle_speed_Vehicle_speed_ReadData_DataServices_Vehicle_speed_Vehicle_speed_ReadData: start-on-event=DataServices_Vehicle_speed_Vehicle_speed_ReadData, operation=DataServices_Vehicle_speed_Vehicle_speed.ReadData
        OIT_DataServices_VCU_PowerMaxAllowed_parameter3_DCDCPower_ConditionCheckRead_DataServices_VCU_PowerMaxAllowed_parameter305EED3D6: start-on-event=DataServices_VCU_PowerMaxAllowed_parameter3_DCDCPower_ConditionCheckRead, operation=DataServices_VCU_PowerMaxAllowed_parameter3_DCDCPower.ConditionCheckRead
        OIT_DataServices_VCU_PowerMaxAllowed_parameter3_DCDCPower_ReadData_DataServices_VCU_PowerMaxAllowed_parameter3_DCDCPowerD604B851: start-on-event=DataServices_VCU_PowerMaxAllowed_parameter3_DCDCPower_ReadData, operation=DataServices_VCU_PowerMaxAllowed_parameter3_DCDCPower.ReadData
        OIT_DataServices_Read_Write_coding_data_string_CDS_CDS_Short_VIN_High_Byte_7_WriteData_DataServices_Read_Write_coding_da9D2B3379: start-on-event=DataServices_Read_Write_coding_data_string_CDS_CDS_Short_VIN_High_Byte_7_WriteData, operation=DataServices_Read_Write_coding_data_string_CDS_CDS_Short_VIN_High_Byte_7.WriteData
        OIT_DataServices_Read_Write_coding_data_string_CDS_CDS_Short_VIN_High_Byte_7_ConditionCheckRead_DataServices_Read_Write_4B9A6589: start-on-event=DataServices_Read_Write_coding_data_string_CDS_CDS_Short_VIN_High_Byte_7_ConditionCheckRead, operation=DataServices_Read_Write_coding_data_string_CDS_CDS_Short_VIN_High_Byte_7.ConditionCheckRead
        OIT_DataServices_Read_Write_coding_data_string_CDS_CDS_Short_VIN_High_Byte_7_ReadData_DataServices_Read_Write_coding_dat181C0BFC: start-on-event=DataServices_Read_Write_coding_data_string_CDS_CDS_Short_VIN_High_Byte_7_ReadData, operation=DataServices_Read_Write_coding_data_string_CDS_CDS_Short_VIN_High_Byte_7.ReadData
        OIT_DataServices_Read_Write_coding_data_string_CDS_Reserved1_WriteData_DataServices_Read_Write_coding_data_string_CDS_ReE0D3CD3D: start-on-event=DataServices_Read_Write_coding_data_string_CDS_Reserved1_WriteData, operation=DataServices_Read_Write_coding_data_string_CDS_Reserved1.WriteData
        OIT_DataServices_Read_Write_coding_data_string_CDS_Reserved1_ConditionCheckRead_DataServices_Read_Write_coding_data_striB4BAEEF2: start-on-event=DataServices_Read_Write_coding_data_string_CDS_Reserved1_ConditionCheckRead, operation=DataServices_Read_Write_coding_data_string_CDS_Reserved1.ConditionCheckRead
        OIT_DataServices_Read_Write_coding_data_string_CDS_Reserved1_ReadData_DataServices_Read_Write_coding_data_string_CDS_ResF87BAC18: start-on-event=DataServices_Read_Write_coding_data_string_CDS_Reserved1_ReadData, operation=DataServices_Read_Write_coding_data_string_CDS_Reserved1.ReadData
        OIT_DataServices_Read_Write_coding_data_string_CDS_CDS_Short_VIN_High_Byte_2_WriteData_DataServices_Read_Write_coding_daC3DE64C8: start-on-event=DataServices_Read_Write_coding_data_string_CDS_CDS_Short_VIN_High_Byte_2_WriteData, operation=DataServices_Read_Write_coding_data_string_CDS_CDS_Short_VIN_High_Byte_2.WriteData
        OIT_DataServices_Read_Write_coding_data_string_CDS_CDS_Short_VIN_High_Byte_2_ConditionCheckRead_DataServices_Read_Write_96084555: start-on-event=DataServices_Read_Write_coding_data_string_CDS_CDS_Short_VIN_High_Byte_2_ConditionCheckRead, operation=DataServices_Read_Write_coding_data_string_CDS_CDS_Short_VIN_High_Byte_2.ConditionCheckRead
        OIT_DataServices_Read_Write_coding_data_string_CDS_CDS_Short_VIN_High_Byte_2_ReadData_DataServices_Read_Write_coding_datAE476F4D: start-on-event=DataServices_Read_Write_coding_data_string_CDS_CDS_Short_VIN_High_Byte_2_ReadData, operation=DataServices_Read_Write_coding_data_string_CDS_CDS_Short_VIN_High_Byte_2.ReadData
        OIT_DataServices_VCU_PowerMaxAllowed_parameter3_MCUPower_ConditionCheckRead_DataServices_VCU_PowerMaxAllowed_parameter3_0B9EF9AE: start-on-event=DataServices_VCU_PowerMaxAllowed_parameter3_MCUPower_ConditionCheckRead, operation=DataServices_VCU_PowerMaxAllowed_parameter3_MCUPower.ConditionCheckRead
        OIT_DataServices_VCU_PowerMaxAllowed_parameter3_MCUPower_ReadData_DataServices_VCU_PowerMaxAllowed_parameter3_MCUPower_ReadData: start-on-event=DataServices_VCU_PowerMaxAllowed_parameter3_MCUPower_ReadData, operation=DataServices_VCU_PowerMaxAllowed_parameter3_MCUPower.ReadData
        OIT_DataServices_VCU_PowerMaxAllowed_parameter2_MCUFeedbackPowerLimit_ConditionCheckRead_DataServices_VCU_PowerMaxAlloweF62D9E50: start-on-event=DataServices_VCU_PowerMaxAllowed_parameter2_MCUFeedbackPowerLimit_ConditionCheckRead, operation=DataServices_VCU_PowerMaxAllowed_parameter2_MCUFeedbackPowerLimit.ConditionCheckRead
        OIT_DataServices_VCU_PowerMaxAllowed_parameter2_MCUFeedbackPowerLimit_ReadData_DataServices_VCU_PowerMaxAllowed_paramete4CBE60F0: start-on-event=DataServices_VCU_PowerMaxAllowed_parameter2_MCUFeedbackPowerLimit_ReadData, operation=DataServices_VCU_PowerMaxAllowed_parameter2_MCUFeedbackPowerLimit.ReadData
        OIT_DataServices_VCU_PowerMaxAllowed_parameter1_VCU_DCDCPowerLimit_ConditionCheckRead_DataServices_VCU_PowerMaxAllowed_p9BBCE11C: start-on-event=DataServices_VCU_PowerMaxAllowed_parameter1_VCU_DCDCPowerLimit_ConditionCheckRead, operation=DataServices_VCU_PowerMaxAllowed_parameter1_VCU_DCDCPowerLimit.ConditionCheckRead
        OIT_DataServices_VCU_PowerMaxAllowed_parameter1_VCU_DCDCPowerLimit_ReadData_DataServices_VCU_PowerMaxAllowed_parameter1_51A70066: start-on-event=DataServices_VCU_PowerMaxAllowed_parameter1_VCU_DCDCPowerLimit_ReadData, operation=DataServices_VCU_PowerMaxAllowed_parameter1_VCU_DCDCPowerLimit.ReadData
        OIT_DataServices_VCU_control_main_relay_Mainrelay2_ConditionCheckRead_DataServices_VCU_control_main_relay_Mainrelay2_Con21E0387D: start-on-event=DataServices_VCU_control_main_relay_Mainrelay2_ConditionCheckRead, operation=DataServices_VCU_control_main_relay_Mainrelay2.ConditionCheckRead
        OIT_DataServices_VCU_control_main_relay_Mainrelay2_ReadData_DataServices_VCU_control_main_relay_Mainrelay2_ReadData: start-on-event=DataServices_VCU_control_main_relay_Mainrelay2_ReadData, operation=DataServices_VCU_control_main_relay_Mainrelay2.ReadData
        OIT_DataServices_PWT_vehicle_fault_PWT_ErrorLevel3_ConditionCheckRead_DataServices_PWT_vehicle_fault_PWT_ErrorLevel3_Con4E0F548E: start-on-event=DataServices_PWT_vehicle_fault_PWT_ErrorLevel3_ConditionCheckRead, operation=DataServices_PWT_vehicle_fault_PWT_ErrorLevel3.ConditionCheckRead
        OIT_DataServices_PWT_vehicle_fault_PWT_ErrorLevel3_ReadData_DataServices_PWT_vehicle_fault_PWT_ErrorLevel3_ReadData: start-on-event=DataServices_PWT_vehicle_fault_PWT_ErrorLevel3_ReadData, operation=DataServices_PWT_vehicle_fault_PWT_ErrorLevel3.ReadData
        OIT_DataServices_VCU_PowerMaxAllowed_parameter3_ACSystemPower_ConditionCheckRead_DataServices_VCU_PowerMaxAllowed_parameF361A48C: start-on-event=DataServices_VCU_PowerMaxAllowed_parameter3_ACSystemPower_ConditionCheckRead, operation=DataServices_VCU_PowerMaxAllowed_parameter3_ACSystemPower.ConditionCheckRead
        OIT_DataServices_VCU_PowerMaxAllowed_parameter3_ACSystemPower_ReadData_DataServices_VCU_PowerMaxAllowed_parameter3_ACSysC391405F: start-on-event=DataServices_VCU_PowerMaxAllowed_parameter3_ACSystemPower_ReadData, operation=DataServices_VCU_PowerMaxAllowed_parameter3_ACSystemPower.ReadData
        OIT_DataServices_Vehicle_State_Ignition_Switch_Signal_ConditionCheckRead_DataServices_Vehicle_State_Ignition_Switch_SignF0F29047: start-on-event=DataServices_Vehicle_State_Ignition_Switch_Signal_ConditionCheckRead, operation=DataServices_Vehicle_State_Ignition_Switch_Signal.ConditionCheckRead
        OIT_DataServices_Vehicle_State_Ignition_Switch_Signal_ReadData_DataServices_Vehicle_State_Ignition_Switch_Signal_ReadData: start-on-event=DataServices_Vehicle_State_Ignition_Switch_Signal_ReadData, operation=DataServices_Vehicle_State_Ignition_Switch_Signal.ReadData
        OIT_DataServices_ECU_application_software_ASW_version_number_No_functional_content_change_ConditionCheckRead_DataService31991CBE: start-on-event=DataServices_ECU_application_software_ASW_version_number_No_functional_content_change_ConditionCheckRead, operation=DataServices_ECU_application_software_ASW_version_number_No_functional_content_change.ConditionCheckRead
        OIT_DataServices_ECU_application_software_ASW_version_number_No_functional_content_change_ReadData_DataServices_ECU_appl87AA0CA1: start-on-event=DataServices_ECU_application_software_ASW_version_number_No_functional_content_change_ReadData, operation=DataServices_ECU_application_software_ASW_version_number_No_functional_content_change.ReadData
        OIT_DataServices_Read_Write_coding_data_string_CDS_CDS_Short_VIN_High_Byte_1_WriteData_DataServices_Read_Write_coding_daF672A9A7: start-on-event=DataServices_Read_Write_coding_data_string_CDS_CDS_Short_VIN_High_Byte_1_WriteData, operation=DataServices_Read_Write_coding_data_string_CDS_CDS_Short_VIN_High_Byte_1.WriteData
        OIT_DataServices_Read_Write_coding_data_string_CDS_CDS_Short_VIN_High_Byte_1_ConditionCheckRead_DataServices_Read_Write_6BA958DE: start-on-event=DataServices_Read_Write_coding_data_string_CDS_CDS_Short_VIN_High_Byte_1_ConditionCheckRead, operation=DataServices_Read_Write_coding_data_string_CDS_CDS_Short_VIN_High_Byte_1.ConditionCheckRead
        OIT_DataServices_Read_Write_coding_data_string_CDS_CDS_Short_VIN_High_Byte_1_ReadData_DataServices_Read_Write_coding_dat755EB11D: start-on-event=DataServices_Read_Write_coding_data_string_CDS_CDS_Short_VIN_High_Byte_1_ReadData, operation=DataServices_Read_Write_coding_data_string_CDS_CDS_Short_VIN_High_Byte_1.ReadData
        OIT_DataServices_HV_Status_and_Charging_Status_HV_status_and_charging_status_ConditionCheckRead_DataServices_HV_Status_a05993A30: start-on-event=DataServices_HV_Status_and_Charging_Status_HV_status_and_charging_status_ConditionCheckRead, operation=DataServices_HV_Status_and_Charging_Status_HV_status_and_charging_status.ConditionCheckRead
        OIT_DataServices_HV_Status_and_Charging_Status_HV_status_and_charging_status_ReadData_DataServices_HV_Status_and_Chargin89AC0BBC: start-on-event=DataServices_HV_Status_and_Charging_Status_HV_status_and_charging_status_ReadData, operation=DataServices_HV_Status_and_Charging_Status_HV_status_and_charging_status.ReadData
        OIT_DataServices_VCU_PowerMaxAllowed_parameter1_MCUPowerLimit_ConditionCheckRead_DataServices_VCU_PowerMaxAllowed_parameEDB244DC: start-on-event=DataServices_VCU_PowerMaxAllowed_parameter1_MCUPowerLimit_ConditionCheckRead, operation=DataServices_VCU_PowerMaxAllowed_parameter1_MCUPowerLimit.ConditionCheckRead
        OIT_DataServices_VCU_PowerMaxAllowed_parameter1_MCUPowerLimit_ReadData_DataServices_VCU_PowerMaxAllowed_parameter1_MCUPo182E97E4: start-on-event=DataServices_VCU_PowerMaxAllowed_parameter1_MCUPowerLimit_ReadData, operation=DataServices_VCU_PowerMaxAllowed_parameter1_MCUPowerLimit.ReadData
        OIT_DataServices_Read_Write_coding_data_string_CDS_CDS_Short_VIN_High_Byte_5_WriteData_DataServices_Read_Write_coding_da0D33470C: start-on-event=DataServices_Read_Write_coding_data_string_CDS_CDS_Short_VIN_High_Byte_5_WriteData, operation=DataServices_Read_Write_coding_data_string_CDS_CDS_Short_VIN_High_Byte_5.WriteData
        OIT_DataServices_Read_Write_coding_data_string_CDS_CDS_Short_VIN_High_Byte_5_ConditionCheckRead_DataServices_Read_Write_E2A4737B: start-on-event=DataServices_Read_Write_coding_data_string_CDS_CDS_Short_VIN_High_Byte_5_ConditionCheckRead, operation=DataServices_Read_Write_coding_data_string_CDS_CDS_Short_VIN_High_Byte_5.ConditionCheckRead
        OIT_DataServices_Read_Write_coding_data_string_CDS_CDS_Short_VIN_High_Byte_5_ReadData_DataServices_Read_Write_coding_dat3CDD9DA3: start-on-event=DataServices_Read_Write_coding_data_string_CDS_CDS_Short_VIN_High_Byte_5_ReadData, operation=DataServices_Read_Write_coding_data_string_CDS_CDS_Short_VIN_High_Byte_5.ReadData
        OIT_DataServices_VCU_PowerMaxAllowed_parameter3_PackPTCPower_ConditionCheckRead_DataServices_VCU_PowerMaxAllowed_paramet561AD71C: start-on-event=DataServices_VCU_PowerMaxAllowed_parameter3_PackPTCPower_ConditionCheckRead, operation=DataServices_VCU_PowerMaxAllowed_parameter3_PackPTCPower.ConditionCheckRead
        OIT_DataServices_VCU_PowerMaxAllowed_parameter3_PackPTCPower_ReadData_DataServices_VCU_PowerMaxAllowed_parameter3_PackPTBB05F6A1: start-on-event=DataServices_VCU_PowerMaxAllowed_parameter3_PackPTCPower_ReadData, operation=DataServices_VCU_PowerMaxAllowed_parameter3_PackPTCPower.ReadData
        OIT_DataServices_Electronic_lock_state_Electronic_lock_state_ConditionCheckRead_DataServices_Electronic_lock_state_Elect70E520EE: start-on-event=DataServices_Electronic_lock_state_Electronic_lock_state_ConditionCheckRead, operation=DataServices_Electronic_lock_state_Electronic_lock_state.ConditionCheckRead
        OIT_DataServices_Electronic_lock_state_Electronic_lock_state_ReadData_DataServices_Electronic_lock_state_Electronic_lock734044AE: start-on-event=DataServices_Electronic_lock_state_Electronic_lock_state_ReadData, operation=DataServices_Electronic_lock_state_Electronic_lock_state.ReadData
        OIT_DataServices_BS_base_information4_VCU_BS_Hcurrent_ConditionCheckRead_DataServices_BS_base_information4_VCU_BS_HcurreBB88EB99: start-on-event=DataServices_BS_base_information4_VCU_BS_Hcurrent_ConditionCheckRead, operation=DataServices_BS_base_information4_VCU_BS_Hcurrent.ConditionCheckRead
        OIT_DataServices_BS_base_information4_VCU_BS_Hcurrent_ReadData_DataServices_BS_base_information4_VCU_BS_Hcurrent_ReadData: start-on-event=DataServices_BS_base_information4_VCU_BS_Hcurrent_ReadData, operation=DataServices_BS_base_information4_VCU_BS_Hcurrent.ReadData
        OIT_DataServices_BS_base_information4_T_BATT_ConditionCheckRead_DataServices_BS_base_information4_T_BATT_ConditionCheckRead: start-on-event=DataServices_BS_base_information4_T_BATT_ConditionCheckRead, operation=DataServices_BS_base_information4_T_BATT.ConditionCheckRead
        OIT_DataServices_BS_base_information4_T_BATT_ReadData_DataServices_BS_base_information4_T_BATT_ReadData: start-on-event=DataServices_BS_base_information4_T_BATT_ReadData, operation=DataServices_BS_base_information4_T_BATT.ReadData
        OIT_DataServices_BS_base_information4_SOF_V2_ConditionCheckRead_DataServices_BS_base_information4_SOF_V2_ConditionCheckRead: start-on-event=DataServices_BS_base_information4_SOF_V2_ConditionCheckRead, operation=DataServices_BS_base_information4_SOF_V2.ConditionCheckRead
        OIT_DataServices_BS_base_information4_SOF_V2_ReadData_DataServices_BS_base_information4_SOF_V2_ReadData: start-on-event=DataServices_BS_base_information4_SOF_V2_ReadData, operation=DataServices_BS_base_information4_SOF_V2.ReadData
        OIT_DataServices_BS_base_information4_SOH_ConditionCheckRead_DataServices_BS_base_information4_SOH_ConditionCheckRead: start-on-event=DataServices_BS_base_information4_SOH_ConditionCheckRead, operation=DataServices_BS_base_information4_SOH.ConditionCheckRead
        OIT_DataServices_BS_base_information4_SOH_ReadData_DataServices_BS_base_information4_SOH_ReadData: start-on-event=DataServices_BS_base_information4_SOH_ReadData, operation=DataServices_BS_base_information4_SOH.ReadData
        OIT_DataServices_BS_base_information4_BS_SOC_ConditionCheckRead_DataServices_BS_base_information4_BS_SOC_ConditionCheckRead: start-on-event=DataServices_BS_base_information4_BS_SOC_ConditionCheckRead, operation=DataServices_BS_base_information4_BS_SOC.ConditionCheckRead
        OIT_DataServices_BS_base_information4_BS_SOC_ReadData_DataServices_BS_base_information4_BS_SOC_ReadData: start-on-event=DataServices_BS_base_information4_BS_SOC_ReadData, operation=DataServices_BS_base_information4_BS_SOC.ReadData
        OIT_DataServices_BS_base_information4_SOF_V1_ConditionCheckRead_DataServices_BS_base_information4_SOF_V1_ConditionCheckRead: start-on-event=DataServices_BS_base_information4_SOF_V1_ConditionCheckRead, operation=DataServices_BS_base_information4_SOF_V1.ConditionCheckRead
        OIT_DataServices_BS_base_information4_SOF_V1_ReadData_DataServices_BS_base_information4_SOF_V1_ReadData: start-on-event=DataServices_BS_base_information4_SOF_V1_ReadData, operation=DataServices_BS_base_information4_SOF_V1.ReadData
        OIT_DataServices_HV_part_fault_information_HV_part_fault_information1_WriteData_DataServices_HV_part_fault_information_H883446EB: start-on-event=DataServices_HV_part_fault_information_HV_part_fault_information1_WriteData, operation=DataServices_HV_part_fault_information_HV_part_fault_information1.WriteData
        OIT_DataServices_HV_part_fault_information_HV_part_fault_information1_ConditionCheckRead_DataServices_HV_part_fault_info7B7DA64E: start-on-event=DataServices_HV_part_fault_information_HV_part_fault_information1_ConditionCheckRead, operation=DataServices_HV_part_fault_information_HV_part_fault_information1.ConditionCheckRead
        OIT_DataServices_HV_part_fault_information_HV_part_fault_information1_ReadData_DataServices_HV_part_fault_information_HV096E923D: start-on-event=DataServices_HV_part_fault_information_HV_part_fault_information1_ReadData, operation=DataServices_HV_part_fault_information_HV_part_fault_information1.ReadData
        OIT_DataServices_HV_part_fault_information_HV_part_fault_information3_WriteData_DataServices_HV_part_fault_information_H50D38183: start-on-event=DataServices_HV_part_fault_information_HV_part_fault_information3_WriteData, operation=DataServices_HV_part_fault_information_HV_part_fault_information3.WriteData
        OIT_DataServices_HV_part_fault_information_HV_part_fault_information3_ConditionCheckRead_DataServices_HV_part_fault_infoD7AC9689: start-on-event=DataServices_HV_part_fault_information_HV_part_fault_information3_ConditionCheckRead, operation=DataServices_HV_part_fault_information_HV_part_fault_information3.ConditionCheckRead
        OIT_DataServices_HV_part_fault_information_HV_part_fault_information3_ReadData_DataServices_HV_part_fault_information_HV1A98FB02: start-on-event=DataServices_HV_part_fault_information_HV_part_fault_information3_ReadData, operation=DataServices_HV_part_fault_information_HV_part_fault_information3.ReadData
        OIT_DataServices_HV_part_fault_information_HV_part_fault_information2_WriteData_DataServices_HV_part_fault_information_H3CA06237: start-on-event=DataServices_HV_part_fault_information_HV_part_fault_information2_WriteData, operation=DataServices_HV_part_fault_information_HV_part_fault_information2.WriteData
        OIT_DataServices_HV_part_fault_information_HV_part_fault_information2_ConditionCheckRead_DataServices_HV_part_fault_info6C7C8DCA: start-on-event=DataServices_HV_part_fault_information_HV_part_fault_information2_ConditionCheckRead, operation=DataServices_HV_part_fault_information_HV_part_fault_information2.ConditionCheckRead
        OIT_DataServices_HV_part_fault_information_HV_part_fault_information2_ReadData_DataServices_HV_part_fault_information_HVFEDB4CBD: start-on-event=DataServices_HV_part_fault_information_HV_part_fault_information2_ReadData, operation=DataServices_HV_part_fault_information_HV_part_fault_information2.ReadData
      207 x runnable:
        R_DiagnosisApp_Cyclic_10ms
          data-receive-point-by-arguments:
            8 x access:
              REC_RTE_R_ChrMgmt_ChrgSts_Enum_tec_ChrMgmt_ChrgSts_Enum: accessed-variable=RTE_R_ChrMgmt_ChrgSts_Enum.tec_ChrMgmt_ChrgSts_Enum
              REC_RTE_R_ComM_IBSVehSpd_kph_tec_ComM_IBSVehSpd_kph: accessed-variable=RTE_R_ComM_IBSVehSpd_kph.tec_ComM_IBSVehSpd_kph
              REC_RTE_R_FctSftyMon_ActGear_Enum_tec_FctSftyMon_ActGear_Enum: accessed-variable=RTE_R_FctSftyMon_ActGear_Enum.tec_FctSftyMon_ActGear_Enum
              REC_RTE_R_IOAbs_BSBattUDc_V_tec_IOAbs_BSBattUDc_V: accessed-variable=RTE_R_IOAbs_BSBattUDc_V.tec_IOAbs_BSBattUDc_V
              REC_RTE_R_ModMgmt_HvSts_Enum_tec_ModMgmt_HvSts_Enum: accessed-variable=RTE_R_ModMgmt_HvSts_Enum.tec_ModMgmt_HvSts_Enum
              REC_RTE_R_RngEst_ClearNVMSucessInfo_tec_RngEst_ClearNVMSucessInfo: accessed-variable=RTE_R_RngEst_ClearNVMSucessInfo.tec_RngEst_ClearNVMSucessInfo
              REC_RTE_R_ComM_NodComFailr_tec_ComM_CHIBSNodComFailr_Flg: accessed-variable=RTE_R_ComM_NodComFailr.tec_ComM_CHIBSNodComFailr_Flg
              REC_SG_IBS_VCU_MotorControl_SigGroup_SG_IBS_VCU_MotorControl_SigGroup: accessed-variable=SG_IBS_VCU_MotorControl_SigGroup.SG_IBS_VCU_MotorControl_SigGroup
          data-send-points:
            access SEND_RTE_P_DiagApp_ClearRangeEstNVMReqInfo_tec_DiagApp_ClearRangeEstNVMReqInfo: accessed-variable=RTE_P_DiagApp_ClearRangeEstNVMReqInfo.tec_DiagApp_ClearRangeEstNVMReqInfo
            access SEND_RTE_P_DiagApp_StayInRunReqInfo_tec_DiagApp_StayInRunReqInfo: accessed-variable=RTE_P_DiagApp_StayInRunReqInfo.tec_DiagApp_StayInRunReqInfo
            access SEND_RTE_P_DiagApp_DisableDCMReqInfo_tec_DiagApp_DisableDCMReqInfo: accessed-variable=RTE_P_DiagApp_DisableDCMReqInfo.tec_DiagApp_DisableDCMReqInfo
        R_DiagnosisApp_Init
        CSDataServices_DID_0x1d05_POD_OBC_OutputDCChargeCurrent_ReadData
          data-receive-point-by-arguments:
            access REC_RTE_R_ComM_OBCOutpIDc_A_tec_ComM_OBCOutpIDc_A: accessed-variable=RTE_R_ComM_OBCOutpIDc_A.tec_ComM_OBCOutpIDc_A
        CSDataServices_DID_0xf1a4_Date_And_Time_Year_ReadData
          data-receive-point-by-arguments:
            access REC_RTE_R_ComM_SGWTimeYearInfo_tec_ComM_SGWTimeYearInfo: accessed-variable=RTE_R_ComM_SGWTimeYearInfo.tec_ComM_SGWTimeYearInfo
        CSDataServices_DID_0x1d01_VCU_VehicleSpeed_ReadData
          data-receive-point-by-arguments:
            access REC_RTE_R_VehMot_VehSpdABS_kph_tec_VehMot_VehSpdABS_kph: accessed-variable=RTE_R_VehMot_VehSpdABS_kph.tec_VehMot_VehSpdABS_kph
        CSDataServices_DID_0x1d08_VCU_HVIL_ReadData
          data-receive-point-by-arguments:
            access REC_RTE_R_IOAbs_HVILPwmFrq_Hz_tec_IOAbs_HVILPwmFrq_Hz: accessed-variable=RTE_R_IOAbs_HVILPwmFrq_Hz.tec_IOAbs_HVILPwmFrq_Hz
        CSDataServices_DID_0x1d11_Mainrelay2_ReadData
          data-receive-point-by-arguments:
            access REC_RTE_R_ComM_BMSNegRlySts_Enum_tec_ComM_BMSNegRlySts_Enum: accessed-variable=RTE_R_ComM_BMSNegRlySts_Enum.tec_ComM_BMSNegRlySts_Enum
        CSDataServices_DID_0x1d07_Electronic_lock_state_ReadData
          data-receive-point-by-arguments:
            access REC_RTE_R_OBCMgmt_ElectcLockCtrlCmd_Enum_tec_OBCMgmt_ElectcLockCtrlCmd_Enum: accessed-variable=RTE_R_OBCMgmt_ElectcLockCtrlCmd_Enum.tec_OBCMgmt_ElectcLockCtrlCmd_Enum
            access REC_RTE_R_ComM_ElectcLockSts_Enum_tec_ComM_ElectcLockSts_Enum: accessed-variable=RTE_R_ComM_ElectcLockSts_Enum.tec_ComM_ElectcLockSts_Enum
        CSDataServices_DID_0x1d01_Accelerator_pedal_sensor_2_voltage_ReadData
          data-receive-point-by-arguments:
            access REC_RTE_R_IOAbs_AccrPedlRdnRaw_mV_tec_IOAbs_AccrPedlRdnRaw_mV: accessed-variable=RTE_R_IOAbs_AccrPedlRdnRaw_mV.tec_IOAbs_AccrPedlRdnRaw_mV
        CSDataServices_DID_0x1d09_New_Bit_Field_ReadData
          data-receive-point-by-arguments:
            access REC_RTE_R_OBCMgmt_S2SwtCtrlCmd_Enum_tec_OBCMgmt_S2SwtCtrlCmd_Enum: accessed-variable=RTE_R_OBCMgmt_S2SwtCtrlCmd_Enum.tec_OBCMgmt_S2SwtCtrlCmd_Enum
            access REC_RTE_R_ComM_S2SwtSts_Enum_tec_ComM_S2SwtSts_Enum: accessed-variable=RTE_R_ComM_S2SwtSts_Enum.tec_ComM_S2SwtSts_Enum
        CSDataServices_DID_0x1d01_Accelerator_pedal_sensor_1_voltage_ReadData
          data-receive-point-by-arguments:
            access REC_RTE_R_IOAbs_AccrPedlMaiRaw_mV_tec_IOAbs_AccrPedlMaiRaw_mV: accessed-variable=RTE_R_IOAbs_AccrPedlMaiRaw_mV.tec_IOAbs_AccrPedlMaiRaw_mV
        CSDataServices_DID_0xf1a4_Date_And_Time_Month_ReadData
          data-receive-point-by-arguments:
            access REC_RTE_R_ComM_SGWTimeMonthInfo_tec_ComM_SGWTimeMonthInfo: accessed-variable=RTE_R_ComM_SGWTimeMonthInfo.tec_ComM_SGWTimeMonthInfo
        CSDataServices_DID_0x1d05_POD_OBC_InputACVoltage_ReadData
          data-receive-point-by-arguments:
            access REC_RTE_R_ComM_OBCInpUAc_V_tec_ComM_OBCInpUAc_V: accessed-variable=RTE_R_ComM_OBCInpUAc_V.tec_ComM_OBCInpUAc_V
        CSDataServices_DID_0xf1a6_SOC_ReadData
          data-receive-point-by-arguments:
            access REC_RTE_R_ComM_BMSBattDispSOC_pct_tec_ComM_BMSBattDispSOC_pct: accessed-variable=RTE_R_ComM_BMSBattDispSOC_pct.tec_ComM_BMSBattDispSOC_pct
        CSDataServices_DID_0xf1a0_Ignition_Switch_Signal_ReadData
          data-receive-point-by-arguments:
            access REC_RTE_R_ComM_CGWVehStatusInfo_tec_ComM_CGWVehStatusInfo: accessed-variable=RTE_R_ComM_CGWVehStatusInfo.tec_ComM_CGWVehStatusInfo
        CSDataServices_DID_0xf1a7_Gear_ReadData
          data-receive-point-by-arguments:
            access REC_RTE_R_FctSftyMon_ActGear_Enum_tec_FctSftyMon_ActGear_Enum: accessed-variable=RTE_R_FctSftyMon_ActGear_Enum.tec_FctSftyMon_ActGear_Enum
        CSDataServices_DID_0x1d01_VCU_AccelerationPedal_ReadData
          data-receive-point-by-arguments:
            access REC_RTE_R_ChassisMgmt_AccrPedlRawPosnInfo_tec_ChassisMgmt_AccrPedlRawPosnInfo: accessed-variable=RTE_R_ChassisMgmt_AccrPedlRawPosnInfo.tec_ChassisMgmt_AccrPedlRawPosnInfo
        CSDataServices_DID_0x1d11_Mainrealy1_ReadData
          data-receive-point-by-arguments:
            access REC_RTE_R_ComM_BMSPosRlySts_Enum_tec_ComM_BMSPosRlySts_Enum: accessed-variable=RTE_R_ComM_BMSPosRlySts_Enum.tec_ComM_BMSPosRlySts_Enum
            access REC_RTE_R_HvMgmt_ReqModBMS_Enum_tec_HvMgmt_ReqModBMS_Enum: accessed-variable=RTE_R_HvMgmt_ReqModBMS_Enum.tec_HvMgmt_ReqModBMS_Enum
            access REC_RTE_R_ChrMgmt_PosRlyReqSts_Enum_tec_ChrMgmt_PosRlyReqSts_Enum: accessed-variable=RTE_R_ChrMgmt_PosRlyReqSts_Enum.tec_ChrMgmt_PosRlyReqSts_Enum
        CSDataServices_DID_0xf1a4_Date_And_Time_Second_ReadData
          data-receive-point-by-arguments:
            access REC_RTE_R_ComM_SGWTimeSecondInfo_tec_ComM_SGWTimeSecondInfo: accessed-variable=RTE_R_ComM_SGWTimeSecondInfo.tec_ComM_SGWTimeSecondInfo
        CSDataServices_DID_0xf1a4_Date_And_Time_Minute_ReadData
          data-receive-point-by-arguments:
            access REC_RTE_R_ComM_SGWTimeMinuteInfo_tec_ComM_SGWTimeMinuteInfo: accessed-variable=RTE_R_ComM_SGWTimeMinuteInfo.tec_ComM_SGWTimeMinuteInfo
        CSDataServices_DID_0x1d05_POD_OBC_OutputDCChargeVoltage_ReadData
          data-receive-point-by-arguments:
            access REC_RTE_R_ComM_OBCOutpUDc_V_tec_ComM_OBCOutpUDc_V: accessed-variable=RTE_R_ComM_OBCOutpUDc_V.tec_ComM_OBCOutpUDc_V
        CSDataServices_DID_0xf1a1_Battery_Voltage_ReadData
          data-receive-point-by-arguments:
            access REC_RTE_R_ComM_BSBatVltHlResInfo_tec_ComM_BSBatVltHlResInfo: accessed-variable=RTE_R_ComM_BSBatVltHlResInfo.tec_ComM_BSBatVltHlResInfo
        CSDataServices_DID_0xf1a2_Total_Odometer_ReadData
          data-receive-point-by-arguments:
            access REC_RTE_R_ComM_IVIOdometerInfo_tec_ComM_IVIOdometerInfo: accessed-variable=RTE_R_ComM_IVIOdometerInfo.tec_ComM_IVIOdometerInfo
        CSDataServices_DID_0xf1a3_Vehicle_speed_ReadData
          data-receive-point-by-arguments:
            access REC_RTE_R_ComM_IBSVehSpd_kph_tec_ComM_IBSVehSpd_kph: accessed-variable=RTE_R_ComM_IBSVehSpd_kph.tec_ComM_IBSVehSpd_kph
        CSDataServices_DID_0x1d05_VCU_OBC_ChargeCurrentCommand_ReadData
          data-receive-point-by-arguments:
            access REC_RTE_R_OBCMgmt_ReqOBCIDc_A_tec_OBCMgmt_ReqOBCIDc_A: accessed-variable=RTE_R_OBCMgmt_ReqOBCIDc_A.tec_OBCMgmt_ReqOBCIDc_A
        CSDataServices_DID_0xf1a5_VCU_HVStatus_ReadData
          data-receive-point-by-arguments:
            access REC_RTE_R_ModMgmt_HvSts_Enum_tec_ModMgmt_HvSts_Enum: accessed-variable=RTE_R_ModMgmt_HvSts_Enum.tec_ModMgmt_HvSts_Enum
        CSDataServices_DID_0xf1a4_Date_And_Time_Hour_ReadData
          data-receive-point-by-arguments:
            access REC_RTE_R_ComM_SGWTimeHourInfo_tec_ComM_SGWTimeHourInfo: accessed-variable=RTE_R_ComM_SGWTimeHourInfo.tec_ComM_SGWTimeHourInfo
        CSDataServices_DID_0xf1a4_Date_And_Time_Day_ReadData
          data-receive-point-by-arguments:
            access REC_RTE_R_ComM_SGWTimeDayInfo_tec_ComM_SGWTimeDayInfo: accessed-variable=RTE_R_ComM_SGWTimeDayInfo.tec_ComM_SGWTimeDayInfo
        DataServices_VCU_PowerMaxAllowed_parameter2_BMSDisChgPowerLimit_ConditionCheckRead
        DataServices_VCU_PowerMaxAllowed_parameter2_BMSDisChgPowerLimit_ReadData
          data-receive-point-by-arguments:
            access REC_RTE_R_ComM_BMSBattDchaIDc_A_tec_ComM_BMSBattDchaIDc_A: accessed-variable=RTE_R_ComM_BMSBattDchaIDc_A.tec_ComM_BMSBattDchaIDc_A
            access REC_RTE_R_ComM_BMSBattPckUDc_V_tec_ComM_BMSBattPckUDc_V: accessed-variable=RTE_R_ComM_BMSBattPckUDc_V.tec_ComM_BMSBattPckUDc_V
        DataServices_AC_charging_parameter_POD_OBC_OutputDCChargeCurrent_ConditionCheckRead
        DataServices_AC_charging_parameter_POD_OBC_OutputDCChargeCurrent_ReadData
          data-receive-point-by-arguments:
            access REC_RTE_R_ComM_OBCOutpIDc_A_tec_ComM_OBCOutpIDc_A: accessed-variable=RTE_R_ComM_OBCOutpIDc_A.tec_ComM_OBCOutpIDc_A
        DataServices_AC_charging_parameter_POD_OBC_OutputDCChargeVoltage_ConditionCheckRead
        DataServices_AC_charging_parameter_POD_OBC_OutputDCChargeVoltage_ReadData
          data-receive-point-by-arguments:
            access REC_RTE_R_ComM_OBCOutpUDc_V_tec_ComM_OBCOutpUDc_V: accessed-variable=RTE_R_ComM_OBCOutpUDc_V.tec_ComM_OBCOutpUDc_V
        DataServices_Date_And_Time_Date_And_Time_Hour_ConditionCheckRead
        DataServices_Date_And_Time_Date_And_Time_Hour_ReadData
          data-receive-point-by-arguments:
            access REC_RTE_R_ComM_SGWTimeHourInfo_tec_ComM_SGWTimeHourInfo: accessed-variable=RTE_R_ComM_SGWTimeHourInfo.tec_ComM_SGWTimeHourInfo
        DataServices_DC_Charging_port_Temperature_POD_DCInletTempB_ConditionCheckRead
        DataServices_DC_Charging_port_Temperature_POD_DCInletTempB_ReadData
          data-receive-point-by-arguments:
            access REC_RTE_R_ComM_DcInletBTemp_C_tec_ComM_DcInletBTemp_C: accessed-variable=RTE_R_ComM_DcInletBTemp_C.tec_ComM_DcInletBTemp_C
        DataServices_Driver_Mode_Driver_Mode_ConditionCheckRead
        DataServices_Driver_Mode_Driver_Mode_ReadData
          data-receive-point-by-arguments:
            access REC_RTE_R_ModMgmt_ActDrvMod_Enum_tec_ModMgmt_ActDrvMod_Enum: accessed-variable=RTE_R_ModMgmt_ActDrvMod_Enum.tec_ModMgmt_ActDrvMod_Enum
        DataServices_VCU_PowerMaxAllowed_parameter3_V2LPower_ConditionCheckRead
        DataServices_VCU_PowerMaxAllowed_parameter3_V2LPower_ReadData
          data-receive-point-by-arguments:
            access REC_RTE_R_EgyMgmt_V2LPwrCnsCalcn_Kw_tec_EgyMgmt_V2LPwrCnsCalcn_Kw: accessed-variable=RTE_R_EgyMgmt_V2LPwrCnsCalcn_Kw.tec_EgyMgmt_V2LPwrCnsCalcn_Kw
        DataServices_VCU_control_S2_status_New_Bit_Field_ConditionCheckRead
        DataServices_VCU_control_S2_status_New_Bit_Field_ReadData
          data-receive-point-by-arguments:
            access REC_RTE_R_ComM_S2SwtSts_Enum_tec_ComM_S2SwtSts_Enum: accessed-variable=RTE_R_ComM_S2SwtSts_Enum.tec_ComM_S2SwtSts_Enum
            access REC_RTE_R_OBCMgmt_S2SwtCtrlCmd_Enum_tec_OBCMgmt_S2SwtCtrlCmd_Enum: accessed-variable=RTE_R_OBCMgmt_S2SwtCtrlCmd_Enum.tec_OBCMgmt_S2SwtCtrlCmd_Enum
        DataServices_Gear_Gear_ConditionCheckRead
        DataServices_Gear_Gear_ReadData
          data-receive-point-by-arguments:
            access REC_RTE_R_FctSftyMon_ActGear_Enum_tec_FctSftyMon_ActGear_Enum: accessed-variable=RTE_R_FctSftyMon_ActGear_Enum.tec_FctSftyMon_ActGear_Enum
        DataServices_Date_And_Time_Date_And_Time_Month_ConditionCheckRead
        DataServices_Date_And_Time_Date_And_Time_Month_ReadData
          data-receive-point-by-arguments:
            access REC_RTE_R_ComM_SGWTimeMonthInfo_tec_ComM_SGWTimeMonthInfo: accessed-variable=RTE_R_ComM_SGWTimeMonthInfo.tec_ComM_SGWTimeMonthInfo
        DataServices_Read_Write_coding_data_string_CDS_CDS_Short_VIN_High_Byte_0_WriteData
        DataServices_Read_Write_coding_data_string_CDS_CDS_Short_VIN_High_Byte_0_ConditionCheckRead
        DataServices_Read_Write_coding_data_string_CDS_CDS_Short_VIN_High_Byte_0_ReadData
        DataServices_HV_part_work_mode_HV_part_work_mode1_ConditionCheckRead
        DataServices_HV_part_work_mode_HV_part_work_mode1_ReadData
          data-receive-point-by-arguments:
            access REC_RTE_R_ComM_BMSWrkMod_Enum_tec_ComM_BMSWrkMod_Enum: accessed-variable=RTE_R_ComM_BMSWrkMod_Enum.tec_ComM_BMSWrkMod_Enum
            access REC_RTE_R_ComM_MCUWrkMod_Enum_tec_ComM_MCUWrkMod_Enum: accessed-variable=RTE_R_ComM_MCUWrkMod_Enum.tec_ComM_MCUWrkMod_Enum
        DataServices_ECU_application_software_ASW_version_number_Major_release_ConditionCheckRead
        DataServices_ECU_application_software_ASW_version_number_Major_release_ReadData
        DataServices_PWT_vehicle_fault_PWT_ErrorLevel2_ConditionCheckRead
        DataServices_PWT_vehicle_fault_PWT_ErrorLevel2_ReadData
          data-receive-point-by-arguments:
            8 x access:
              REC_RTE_R_ErrMgmt_AcPause_Flg_tec_ErrMgmt_AcPause_Flg: accessed-variable=RTE_R_ErrMgmt_AcPause_Flg.tec_ErrMgmt_AcPause_Flg
              REC_RTE_R_ErrMgmt_AcStop_Flg_tec_ErrMgmt_AcStop_Flg: accessed-variable=RTE_R_ErrMgmt_AcStop_Flg.tec_ErrMgmt_AcStop_Flg
              REC_RTE_R_ErrMgmt_DcPause_Flg_tec_ErrMgmt_DcPause_Flg: accessed-variable=RTE_R_ErrMgmt_DcPause_Flg.tec_ErrMgmt_DcPause_Flg
              REC_RTE_R_ErrMgmt_DcStop_Flg_tec_ErrMgmt_DcStop_Flg: accessed-variable=RTE_R_ErrMgmt_DcStop_Flg.tec_ErrMgmt_DcStop_Flg
              REC_RTE_R_ErrMgmt_GrdtZeroTq_Flg_tec_ErrMgmt_GrdtZeroTq_Flg: accessed-variable=RTE_R_ErrMgmt_GrdtZeroTq_Flg.tec_ErrMgmt_GrdtZeroTq_Flg
              REC_RTE_R_ErrMgmt_V2LStop_Flg_tec_ErrMgmt_V2LStop_Flg: accessed-variable=RTE_R_ErrMgmt_V2LStop_Flg.tec_ErrMgmt_V2LStop_Flg
              REC_RTE_R_ErrMgmt_VehSpdLimErrLv5_Flg_tec_ErrMgmt_VehSpdLimErrLv5_Flg: accessed-variable=RTE_R_ErrMgmt_VehSpdLimErrLv5_Flg.tec_ErrMgmt_VehSpdLimErrLv5_Flg
              REC_RTE_R_ErrMgmt_VehSpdLimErrLv6_Flg_tec_ErrMgmt_VehSpdLimErrLv6_Flg: accessed-variable=RTE_R_ErrMgmt_VehSpdLimErrLv6_Flg.tec_ErrMgmt_VehSpdLimErrLv6_Flg
        DataServices_VCU_PowerMaxAllowed_parameter2_BMSChgPowerLimit_ConditionCheckRead
        DataServices_VCU_PowerMaxAllowed_parameter2_BMSChgPowerLimit_ReadData
          data-receive-point-by-arguments:
            access REC_RTE_R_ComM_BMSBattFbIDc_A_tec_ComM_BMSBattFbIDc_A: accessed-variable=RTE_R_ComM_BMSBattFbIDc_A.tec_ComM_BMSBattFbIDc_A
            access REC_RTE_R_ComM_BMSBattPckUDc_V_tec_ComM_BMSBattPckUDc_V: accessed-variable=RTE_R_ComM_BMSBattPckUDc_V.tec_ComM_BMSBattPckUDc_V
        DataServices_Read_Write_coding_data_string_CDS_Configuration_WriteData
          data-receive-point-by-arguments:
            access REC_RTE_R_TorqPahMgmt_SpdLmtReadInfo_tec_TorqPahMgmt_SpdLmtReadInfo: accessed-variable=RTE_R_TorqPahMgmt_SpdLmtReadInfo.tec_TorqPahMgmt_SpdLmtReadInfo
            access REC_RTE_R_VotMot_TireRadiusReadInfo_tec_VotMot_TireRadiusReadInfo: accessed-variable=RTE_R_VotMot_TireRadiusReadInfo.tec_VotMot_TireRadiusReadInfo
          data-send-points:
            4 x access:
              SEND_RTE_P_DiagApp_SpdLmtInfo_tec_DiagApp_SpdLmtInfo: accessed-variable=RTE_P_DiagApp_SpdLmtInfo.tec_DiagApp_SpdLmtInfo
              SEND_RTE_P_DiagApp_SpdLmtUpdateInfo_tec_DiagApp_SpdLmtUpdateInfo: accessed-variable=RTE_P_DiagApp_SpdLmtUpdateInfo.tec_DiagApp_SpdLmtUpdateInfo
              SEND_RTE_P_DiagApp_TireRadiusInfo_tec_DiagApp_TireRadiusInfo: accessed-variable=RTE_P_DiagApp_TireRadiusInfo.tec_DiagApp_TireRadiusInfo
              SEND_RTE_P_DiagApp_TireRadiusUpdateInfo_tec_DiagApp_TireRadiusUpdateInfo: accessed-variable=RTE_P_DiagApp_TireRadiusUpdateInfo.tec_DiagApp_TireRadiusUpdateInfo
        DataServices_Read_Write_coding_data_string_CDS_Configuration_ConditionCheckRead
        DataServices_Read_Write_coding_data_string_CDS_Configuration_ReadData
          data-receive-point-by-arguments:
            access REC_RTE_R_VotMot_TireRadiusReadInfo_tec_VotMot_TireRadiusReadInfo: accessed-variable=RTE_R_VotMot_TireRadiusReadInfo.tec_VotMot_TireRadiusReadInfo
        DataServices_VCU_HVStatus_VCU_HVStatus_ConditionCheckRead
        DataServices_VCU_HVStatus_VCU_HVStatus_ReadData
          data-receive-point-by-arguments:
            access REC_RTE_R_ModMgmt_HvSts_Enum_tec_ModMgmt_HvSts_Enum: accessed-variable=RTE_R_ModMgmt_HvSts_Enum.tec_ModMgmt_HvSts_Enum
        DataServices_Battery_Voltage_Battery_Voltage_ConditionCheckRead
        DataServices_Battery_Voltage_Battery_Voltage_ReadData
          data-receive-point-by-arguments:
            access REC_RTE_R_ComM_BSBatVltHlResInfo_tec_ComM_BSBatVltHlResInfo: accessed-variable=RTE_R_ComM_BSBatVltHlResInfo.tec_ComM_BSBatVltHlResInfo
        DataServices_SOC_SOC_ConditionCheckRead
        DataServices_SOC_SOC_ReadData
          data-receive-point-by-arguments:
            access REC_RTE_R_ComM_BMSBattDispSOC_pct_tec_ComM_BMSBattDispSOC_pct: accessed-variable=RTE_R_ComM_BMSBattDispSOC_pct.tec_ComM_BMSBattDispSOC_pct
        DataServices_VCU_PowerMaxAllowed_parameter1_VCU_TCUPowerAllowed_ConditionCheckRead
        DataServices_VCU_PowerMaxAllowed_parameter1_VCU_TCUPowerAllowed_ReadData
          data-receive-point-by-arguments:
            access REC_RTE_R_EgyMgmt_TCUPwrAllwd_W_tec_EgyMgmt_TCUPwrAllwd_W: accessed-variable=RTE_R_EgyMgmt_TCUPwrAllwd_W.tec_EgyMgmt_TCUPwrAllwd_W
        DataServices_Read_Write_coding_data_string_CDS_Reserved3_WriteData
        DataServices_Read_Write_coding_data_string_CDS_Reserved3_ConditionCheckRead
        DataServices_Read_Write_coding_data_string_CDS_Reserved3_ReadData
        DataServices_VCU_Torque_parameter_VCU_RegenTorqueCap_ConditionCheckRead
        DataServices_VCU_Torque_parameter_VCU_RegenTorqueCap_ReadData
          data-receive-point-by-arguments:
            access REC_RTE_R_ChassisMgmt_RgnTqCap_Nm_tec_ChassisMgmt_RgnTqCap_Nm: accessed-variable=RTE_R_ChassisMgmt_RgnTqCap_Nm.tec_ChassisMgmt_RgnTqCap_Nm
        DataServices_AC_charging_parameter_VCU_OBC_ChargeCurrentCommand_ConditionCheckRead
        DataServices_AC_charging_parameter_VCU_OBC_ChargeCurrentCommand_ReadData
          data-receive-point-by-arguments:
            access REC_RTE_R_OBCMgmt_ReqOBCIDc_A_tec_OBCMgmt_ReqOBCIDc_A: accessed-variable=RTE_R_OBCMgmt_ReqOBCIDc_A.tec_OBCMgmt_ReqOBCIDc_A
        DataServices_DC_Charging_port_Temperature_POD_DCInletTempA_ConditionCheckRead
        DataServices_DC_Charging_port_Temperature_POD_DCInletTempA_ReadData
          data-receive-point-by-arguments:
            access REC_RTE_R_ComM_DcInletATemp_C_tec_ComM_DcInletATemp_C: accessed-variable=RTE_R_ComM_DcInletATemp_C.tec_ComM_DcInletATemp_C
        DataServices_Read_Write_coding_data_string_CDS_CDS_CRC_WriteData
        DataServices_Read_Write_coding_data_string_CDS_CDS_CRC_ConditionCheckRead
        DataServices_Read_Write_coding_data_string_CDS_CDS_CRC_ReadData
        DataServices_Chargestatus_Chargestatus_ConditionCheckRead
        DataServices_Chargestatus_Chargestatus_ReadData
          data-receive-point-by-arguments:
            access REC_RTE_R_ChrMgmt_ChrgSts_Enum_tec_ChrMgmt_ChrgSts_Enum: accessed-variable=RTE_R_ChrMgmt_ChrgSts_Enum.tec_ChrMgmt_ChrgSts_Enum
        DataServices_Date_And_Time_Date_And_Time_Second_ConditionCheckRead
        DataServices_Date_And_Time_Date_And_Time_Second_ReadData
          data-receive-point-by-arguments:
            access REC_RTE_R_ComM_SGWTimeSecondInfo_tec_ComM_SGWTimeSecondInfo: accessed-variable=RTE_R_ComM_SGWTimeSecondInfo.tec_ComM_SGWTimeSecondInfo
        DataServices_Date_And_Time_Date_And_Time_Year_ConditionCheckRead
        DataServices_Date_And_Time_Date_And_Time_Year_ReadData
          data-receive-point-by-arguments:
            access REC_RTE_R_ComM_SGWTimeYearInfo_tec_ComM_SGWTimeYearInfo: accessed-variable=RTE_R_ComM_SGWTimeYearInfo.tec_ComM_SGWTimeYearInfo
        DataServices_Read_Write_coding_data_string_CDS_CDS_Short_VIN_High_Byte_3_WriteData
        DataServices_Read_Write_coding_data_string_CDS_CDS_Short_VIN_High_Byte_3_ConditionCheckRead
        DataServices_Read_Write_coding_data_string_CDS_CDS_Short_VIN_High_Byte_3_ReadData
        DataServices_VCU_Torque_parameter_Torque_MinAllowed_ConditionCheckRead
        DataServices_VCU_Torque_parameter_Torque_MinAllowed_ReadData
          data-receive-point-by-arguments:
            access REC_RTE_R_TorqPahMgmt_EmacQstyMinTq_Nm_tec_TorqPahMgmt_EmacQstyMinTq_Nm: accessed-variable=RTE_R_TorqPahMgmt_EmacQstyMinTq_Nm.tec_TorqPahMgmt_EmacQstyMinTq_Nm
        DataServices_HV_part_work_mode_HV_part_work_mode2_ConditionCheckRead
        DataServices_HV_part_work_mode_HV_part_work_mode2_ReadData
          data-receive-point-by-arguments:
            access REC_RTE_R_ComM_DCDCWrkMod_Enum_tec_ComM_DCDCWrkMod_Enum: accessed-variable=RTE_R_ComM_DCDCWrkMod_Enum.tec_ComM_DCDCWrkMod_Enum
            access REC_RTE_R_ComM_OBCChrgSts_Enum_tec_ComM_OBCChrgSts_Enum: accessed-variable=RTE_R_ComM_OBCChrgSts_Enum.tec_ComM_OBCChrgSts_Enum
            access REC_RTE_R_ComM_OBCCCSts_Enum_tec_ComM_OBCCCSts_Enum: accessed-variable=RTE_R_ComM_OBCCCSts_Enum.tec_ComM_OBCCCSts_Enum
        DataServices_Read_Write_coding_data_string_CDS_CDS_Format_Byte_High_Byte_0_WriteData
        DataServices_Read_Write_coding_data_string_CDS_CDS_Format_Byte_High_Byte_0_ConditionCheckRead
        DataServices_Read_Write_coding_data_string_CDS_CDS_Format_Byte_High_Byte_0_ReadData
        DataServices_Date_And_Time_Date_And_Time_Minute_ConditionCheckRead
        DataServices_Date_And_Time_Date_And_Time_Minute_ReadData
          data-receive-point-by-arguments:
            access REC_RTE_R_ComM_SGWTimeMinuteInfo_tec_ComM_SGWTimeMinuteInfo: accessed-variable=RTE_R_ComM_SGWTimeMinuteInfo.tec_ComM_SGWTimeMinuteInfo
        DataServices_Date_And_Time_Date_And_Time_Day_ConditionCheckRead
        DataServices_Date_And_Time_Date_And_Time_Day_ReadData
          data-receive-point-by-arguments:
            access REC_RTE_R_ComM_SGWTimeDayInfo_tec_ComM_SGWTimeDayInfo: accessed-variable=RTE_R_ComM_SGWTimeDayInfo.tec_ComM_SGWTimeDayInfo
        DataServices_Read_Write_coding_data_string_CDS_Version_Byte_1_WriteData
        DataServices_Read_Write_coding_data_string_CDS_Version_Byte_1_ConditionCheckRead
        DataServices_Read_Write_coding_data_string_CDS_Version_Byte_1_ReadData
        DataServices_VCU_PowerMaxAllowed_parameter1_VCU_DisChgPowerLimit_ConditionCheckRead
        DataServices_VCU_PowerMaxAllowed_parameter1_VCU_DisChgPowerLimit_ReadData
          data-receive-point-by-arguments:
            access REC_RTE_R_EgyMgmt_V2LDisChgPwrLmtInfo_tec_EgyMgmt_V2LDisChgPwrLmtInfo: accessed-variable=RTE_R_EgyMgmt_V2LDisChgPwrLmtInfo.tec_EgyMgmt_V2LDisChgPwrLmtInfo
        DataServices_VCU_Torque_parameter_VCU_MCUDesiredTorque_ConditionCheckRead
        DataServices_VCU_Torque_parameter_VCU_MCUDesiredTorque_ReadData
          data-receive-point-by-arguments:
            access REC_RTE_R_TorqPahMgmt_DesMotTq_Nm_tec_TorqPahMgmt_DesMotTq_Nm: accessed-variable=RTE_R_TorqPahMgmt_DesMotTq_Nm.tec_TorqPahMgmt_DesMotTq_Nm
        DataServices_AC_charging_parameter_POD_OBC_InputACVoltage_ConditionCheckRead
        DataServices_AC_charging_parameter_POD_OBC_InputACVoltage_ReadData
          data-receive-point-by-arguments:
            access REC_RTE_R_ComM_OBCInpUAc_V_tec_ComM_OBCInpUAc_V: accessed-variable=RTE_R_ComM_OBCInpUAc_V.tec_ComM_OBCInpUAc_V
        DataServices_VCU_AccPealparameter_VCU_AccelerationPedal_ConditionCheckRead
        DataServices_VCU_AccPealparameter_VCU_AccelerationPedal_ReadData
          data-receive-point-by-arguments:
            access REC_RTE_R_ChassisMgmt_AccrPedlPosn_pct_tec_ChassisMgmt_AccrPedlPosn_pct: accessed-variable=RTE_R_ChassisMgmt_AccrPedlPosn_pct.tec_ChassisMgmt_AccrPedlPosn_pct
        DataServices_VCU_Torque_parameter_Torque_MaxAllowed_ConditionCheckRead
        DataServices_VCU_Torque_parameter_Torque_MaxAllowed_ReadData
          data-receive-point-by-arguments:
            access REC_RTE_R_TorqPahMgmt_EmacQstyMaxTq_Nm_tec_TorqPahMgmt_EmacQstyMaxTq_Nm: accessed-variable=RTE_R_TorqPahMgmt_EmacQstyMaxTq_Nm.tec_TorqPahMgmt_EmacQstyMaxTq_Nm
        DataServices_Read_Write_coding_data_string_CDS_Version_Byte_0_WriteData
        DataServices_Read_Write_coding_data_string_CDS_Version_Byte_0_ConditionCheckRead
        DataServices_Read_Write_coding_data_string_CDS_Version_Byte_0_ReadData
        DataServices_VCU_HV_InterLock_PWM_pfrequency_VCU_HVIL_ConditionCheckRead
        DataServices_VCU_HV_InterLock_PWM_pfrequency_VCU_HVIL_ReadData
          data-receive-point-by-arguments:
            access REC_RTE_R_IOAbs_HVILPwmFrq_Hz_tec_IOAbs_HVILPwmFrq_Hz: accessed-variable=RTE_R_IOAbs_HVILPwmFrq_Hz.tec_IOAbs_HVILPwmFrq_Hz
        DataServices_Total_Odometer_Total_Odometer_ConditionCheckRead
        DataServices_Total_Odometer_Total_Odometer_ReadData
          data-receive-point-by-arguments:
            access REC_RTE_R_ComM_IVIOdometerInfo_tec_ComM_IVIOdometerInfo: accessed-variable=RTE_R_ComM_IVIOdometerInfo.tec_ComM_IVIOdometerInfo
        DataServices_VCU_AccPealparameter_VCU_VehicleSpeed_ConditionCheckRead
        DataServices_VCU_AccPealparameter_VCU_VehicleSpeed_ReadData
          data-receive-point-by-arguments:
            access REC_RTE_R_VehMot_VehSpd_kph_tec_VehMot_VehSpd_kph: accessed-variable=RTE_R_VehMot_VehSpd_kph.tec_VehMot_VehSpd_kph
        DataServices_VCU_AccPealparameter_Accelerator_pedal_sensor_1_voltage_ConditionCheckRead
        DataServices_VCU_AccPealparameter_Accelerator_pedal_sensor_1_voltage_ReadData
          data-receive-point-by-arguments:
            access REC_RTE_R_IOAbs_AccrPedlMaiRaw_mV_tec_IOAbs_AccrPedlMaiRaw_mV: accessed-variable=RTE_R_IOAbs_AccrPedlMaiRaw_mV.tec_IOAbs_AccrPedlMaiRaw_mV
        DataServices_Read_Write_coding_data_string_CDS_Reserved2_WriteData
        DataServices_Read_Write_coding_data_string_CDS_Reserved2_ConditionCheckRead
        DataServices_Read_Write_coding_data_string_CDS_Reserved2_ReadData
        DataServices_VCU_control_main_relay_Mainrealy1_ConditionCheckRead
        DataServices_VCU_control_main_relay_Mainrealy1_ReadData
          data-receive-point-by-arguments:
            access REC_RTE_R_ComM_BMSPosRlySts_Enum_tec_ComM_BMSPosRlySts_Enum: accessed-variable=RTE_R_ComM_BMSPosRlySts_Enum.tec_ComM_BMSPosRlySts_Enum
            access REC_RTE_R_HvMgmt_ReqModBMS_Enum_tec_HvMgmt_ReqModBMS_Enum: accessed-variable=RTE_R_HvMgmt_ReqModBMS_Enum.tec_HvMgmt_ReqModBMS_Enum
        DataServices_PWT_vehicle_fault_PWT_ErrorLevel1_ConditionCheckRead
        DataServices_PWT_vehicle_fault_PWT_ErrorLevel1_ReadData
          data-receive-point-by-arguments:
            access REC_RTE_R_ErrMgmt_VehErrLvl_Enum_tec_ErrMgmt_VehErrLvl_Enum: accessed-variable=RTE_R_ErrMgmt_VehErrLvl_Enum.tec_ErrMgmt_VehErrLvl_Enum
        DataServices_Read_Write_coding_data_string_CDS_CDS_Short_VIN_High_Byte_4_WriteData
        DataServices_Read_Write_coding_data_string_CDS_CDS_Short_VIN_High_Byte_4_ConditionCheckRead
        DataServices_Read_Write_coding_data_string_CDS_CDS_Short_VIN_High_Byte_4_ReadData
        DataServices_VCU_AccPealparameter_Accelerator_pedal_sensor_2_voltage_ConditionCheckRead
        DataServices_VCU_AccPealparameter_Accelerator_pedal_sensor_2_voltage_ReadData
          data-receive-point-by-arguments:
            access REC_RTE_R_IOAbs_AccrPedlRdnRaw_mV_tec_IOAbs_AccrPedlRdnRaw_mV: accessed-variable=RTE_R_IOAbs_AccrPedlRdnRaw_mV.tec_IOAbs_AccrPedlRdnRaw_mV
        DataServices_ECU_application_software_ASW_version_number_Minor_release_ConditionCheckRead
        DataServices_ECU_application_software_ASW_version_number_Minor_release_ReadData
        DataServices_Read_Write_coding_data_string_CDS_CDS_Format_Byte_High_Byte_1_WriteData
        DataServices_Read_Write_coding_data_string_CDS_CDS_Format_Byte_High_Byte_1_ConditionCheckRead
        DataServices_Read_Write_coding_data_string_CDS_CDS_Format_Byte_High_Byte_1_ReadData
        DataServices_Vehicle_speed_Vehicle_speed_ConditionCheckRead
        DataServices_Vehicle_speed_Vehicle_speed_ReadData
          data-receive-point-by-arguments:
            access REC_RTE_R_ComM_IBSVehSpd_kph_tec_ComM_IBSVehSpd_kph: accessed-variable=RTE_R_ComM_IBSVehSpd_kph.tec_ComM_IBSVehSpd_kph
        DataServices_VCU_PowerMaxAllowed_parameter3_DCDCPower_ConditionCheckRead
        DataServices_VCU_PowerMaxAllowed_parameter3_DCDCPower_ReadData
          data-receive-point-by-arguments:
            access REC_RTE_R_EgyMgmt_DCDCPwrCnsCalcn_Kw_tec_EgyMgmt_DCDCPwrCnsCalcn_Kw: accessed-variable=RTE_R_EgyMgmt_DCDCPwrCnsCalcn_Kw.tec_EgyMgmt_DCDCPwrCnsCalcn_Kw
        DataServices_Read_Write_coding_data_string_CDS_CDS_Short_VIN_High_Byte_7_WriteData
        DataServices_Read_Write_coding_data_string_CDS_CDS_Short_VIN_High_Byte_7_ConditionCheckRead
        DataServices_Read_Write_coding_data_string_CDS_CDS_Short_VIN_High_Byte_7_ReadData
        DataServices_Read_Write_coding_data_string_CDS_Reserved1_WriteData
        DataServices_Read_Write_coding_data_string_CDS_Reserved1_ConditionCheckRead
        DataServices_Read_Write_coding_data_string_CDS_Reserved1_ReadData
        DataServices_Read_Write_coding_data_string_CDS_CDS_Short_VIN_High_Byte_2_WriteData
        DataServices_Read_Write_coding_data_string_CDS_CDS_Short_VIN_High_Byte_2_ConditionCheckRead
        DataServices_Read_Write_coding_data_string_CDS_CDS_Short_VIN_High_Byte_2_ReadData
        DataServices_VCU_PowerMaxAllowed_parameter3_MCUPower_ConditionCheckRead
        DataServices_VCU_PowerMaxAllowed_parameter3_MCUPower_ReadData
          data-receive-point-by-arguments:
            access REC_RTE_R_EgyMgmt_MCUPwrCnsCalcn_Kw_tec_EgyMgmt_MCUPwrCnsCalcn_Kw: accessed-variable=RTE_R_EgyMgmt_MCUPwrCnsCalcn_Kw.tec_EgyMgmt_MCUPwrCnsCalcn_Kw
        DataServices_VCU_PowerMaxAllowed_parameter2_MCUFeedbackPowerLimit_ConditionCheckRead
        DataServices_VCU_PowerMaxAllowed_parameter2_MCUFeedbackPowerLimit_ReadData
          data-receive-point-by-arguments:
            access REC_RTE_R_EgyMgmt_MCUFbPwrLmt_Kw_tec_EgyMgmt_MCUFbPwrLmt_Kw: accessed-variable=RTE_R_EgyMgmt_MCUFbPwrLmt_Kw.tec_EgyMgmt_MCUFbPwrLmt_Kw
        DataServices_VCU_PowerMaxAllowed_parameter1_VCU_DCDCPowerLimit_ConditionCheckRead
        DataServices_VCU_PowerMaxAllowed_parameter1_VCU_DCDCPowerLimit_ReadData
          data-receive-point-by-arguments:
            access REC_RTE_R_EgyMgmt_DCDCPwrLmt_Kw_tec_EgyMgmt_DCDCPwrLmt_Kw: accessed-variable=RTE_R_EgyMgmt_DCDCPwrLmt_Kw.tec_EgyMgmt_DCDCPwrLmt_Kw
        DataServices_VCU_control_main_relay_Mainrelay2_ConditionCheckRead
        DataServices_VCU_control_main_relay_Mainrelay2_ReadData
          data-receive-point-by-arguments:
            access REC_RTE_R_ComM_BMSNegRlySts_Enum_tec_ComM_BMSNegRlySts_Enum: accessed-variable=RTE_R_ComM_BMSNegRlySts_Enum.tec_ComM_BMSNegRlySts_Enum
            access REC_RTE_R_ComM_BMSPosRlySts_Enum_tec_ComM_BMSPosRlySts_Enum: accessed-variable=RTE_R_ComM_BMSPosRlySts_Enum.tec_ComM_BMSPosRlySts_Enum
        DataServices_PWT_vehicle_fault_PWT_ErrorLevel3_ConditionCheckRead
        DataServices_PWT_vehicle_fault_PWT_ErrorLevel3_ReadData
          data-receive-point-by-arguments:
            7 x access:
              REC_RTE_R_ErrMgmt_DlyGrdtZeroTq_Flg_tec_ErrMgmt_DlyGrdtZeroTq_Flg: accessed-variable=RTE_R_ErrMgmt_DlyGrdtZeroTq_Flg.tec_ErrMgmt_DlyGrdtZeroTq_Flg
              REC_RTE_R_ErrMgmt_DlyHvDwn_Flg_tec_ErrMgmt_DlyHvDwn_Flg: accessed-variable=RTE_R_ErrMgmt_DlyHvDwn_Flg.tec_ErrMgmt_DlyHvDwn_Flg
              REC_RTE_R_ErrMgmt_EmgyHvDwn_Flg_tec_ErrMgmt_EmgyHvDwn_Flg: accessed-variable=RTE_R_ErrMgmt_EmgyHvDwn_Flg.tec_ErrMgmt_EmgyHvDwn_Flg
              REC_RTE_R_ErrMgmt_Fobd2Hv_Flg_tec_ErrMgmt_Fobd2Hv_Flg: accessed-variable=RTE_R_ErrMgmt_Fobd2Hv_Flg.tec_ErrMgmt_Fobd2Hv_Flg
              REC_RTE_R_ErrMgmt_FobdEgyRcov_Flg_tec_ErrMgmt_FobdEgyRcov_Flg: accessed-variable=RTE_R_ErrMgmt_FobdEgyRcov_Flg.tec_ErrMgmt_FobdEgyRcov_Flg
              REC_RTE_R_ErrMgmt_HvNormDwn_Flg_tec_ErrMgmt_HvNormDwn_Flg: accessed-variable=RTE_R_ErrMgmt_HvNormDwn_Flg.tec_ErrMgmt_HvNormDwn_Flg
              REC_RTE_R_ErrMgmt_ImdtZeroTq_Flg_tec_ErrMgmt_ImdtZeroTq_Flg: accessed-variable=RTE_R_ErrMgmt_ImdtZeroTq_Flg.tec_ErrMgmt_ImdtZeroTq_Flg
        DataServices_VCU_PowerMaxAllowed_parameter3_ACSystemPower_ConditionCheckRead
        DataServices_VCU_PowerMaxAllowed_parameter3_ACSystemPower_ReadData
          data-receive-point-by-arguments:
            access REC_RTE_R_EgyMgmt_ACSysPwrCnsCalcn_Kw_tec_EgyMgmt_ACSysPwrCnsCalcn_Kw: accessed-variable=RTE_R_EgyMgmt_ACSysPwrCnsCalcn_Kw.tec_EgyMgmt_ACSysPwrCnsCalcn_Kw
        DataServices_Vehicle_State_Ignition_Switch_Signal_ConditionCheckRead
        DataServices_Vehicle_State_Ignition_Switch_Signal_ReadData
          data-receive-point-by-arguments:
            access REC_RTE_R_ComM_CGWVehStatusInfo_tec_ComM_CGWVehStatusInfo: accessed-variable=RTE_R_ComM_CGWVehStatusInfo.tec_ComM_CGWVehStatusInfo
        DataServices_ECU_application_software_ASW_version_number_No_functional_content_change_ConditionCheckRead
        DataServices_ECU_application_software_ASW_version_number_No_functional_content_change_ReadData
        DataServices_Read_Write_coding_data_string_CDS_CDS_Short_VIN_High_Byte_1_WriteData
        DataServices_Read_Write_coding_data_string_CDS_CDS_Short_VIN_High_Byte_1_ConditionCheckRead
        DataServices_Read_Write_coding_data_string_CDS_CDS_Short_VIN_High_Byte_1_ReadData
        DataServices_HV_Status_and_Charging_Status_HV_status_and_charging_status_ConditionCheckRead
        DataServices_HV_Status_and_Charging_Status_HV_status_and_charging_status_ReadData
          data-receive-point-by-arguments:
            access REC_RTE_R_ChrMgmt_ChrgSts_Enum_tec_ChrMgmt_ChrgSts_Enum: accessed-variable=RTE_R_ChrMgmt_ChrgSts_Enum.tec_ChrMgmt_ChrgSts_Enum
            access REC_RTE_R_ModMgmt_HvSts_Enum_tec_ModMgmt_HvSts_Enum: accessed-variable=RTE_R_ModMgmt_HvSts_Enum.tec_ModMgmt_HvSts_Enum
        DataServices_VCU_PowerMaxAllowed_parameter1_MCUPowerLimit_ConditionCheckRead
        DataServices_VCU_PowerMaxAllowed_parameter1_MCUPowerLimit_ReadData
          data-receive-point-by-arguments:
            access REC_RTE_R_EgyMgmt_MCUDrvPwrLmt_Kw_tec_EgyMgmt_MCUDrvPwrLmt_Kw: accessed-variable=RTE_R_EgyMgmt_MCUDrvPwrLmt_Kw.tec_EgyMgmt_MCUDrvPwrLmt_Kw
        DataServices_Read_Write_coding_data_string_CDS_CDS_Short_VIN_High_Byte_5_WriteData
        DataServices_Read_Write_coding_data_string_CDS_CDS_Short_VIN_High_Byte_5_ConditionCheckRead
        DataServices_Read_Write_coding_data_string_CDS_CDS_Short_VIN_High_Byte_5_ReadData
        DataServices_VCU_PowerMaxAllowed_parameter3_PackPTCPower_ConditionCheckRead
        DataServices_VCU_PowerMaxAllowed_parameter3_PackPTCPower_ReadData
          data-receive-point-by-arguments:
            access REC_RTE_R_EgyMgmt_PackPTCPwrCnsCalcn_Kw_tec_EgyMgmt_PackPTCPwrCnsCalcn_Kw: accessed-variable=RTE_R_EgyMgmt_PackPTCPwrCnsCalcn_Kw.tec_EgyMgmt_PackPTCPwrCnsCalcn_Kw
        DataServices_Electronic_lock_state_Electronic_lock_state_ConditionCheckRead
        DataServices_Electronic_lock_state_Electronic_lock_state_ReadData
          data-receive-point-by-arguments:
            access REC_RTE_R_ComM_ElectcLockSts_Enum_tec_ComM_ElectcLockSts_Enum: accessed-variable=RTE_R_ComM_ElectcLockSts_Enum.tec_ComM_ElectcLockSts_Enum
            access REC_RTE_R_OBCMgmt_S2SwtCtrlCmd_Enum_tec_OBCMgmt_S2SwtCtrlCmd_Enum: accessed-variable=RTE_R_OBCMgmt_S2SwtCtrlCmd_Enum.tec_OBCMgmt_S2SwtCtrlCmd_Enum
        DataServices_BS_base_information4_VCU_BS_Hcurrent_ConditionCheckRead
        DataServices_BS_base_information4_VCU_BS_Hcurrent_ReadData
          data-receive-point-by-arguments:
            access REC_RTE_R_ComM_BSHCrnt_tec_ComM_BSHCrnt: accessed-variable=RTE_R_ComM_BSHCrnt.tec_ComM_BSHCrnt
        DataServices_BS_base_information4_T_BATT_ConditionCheckRead
        DataServices_BS_base_information4_T_BATT_ReadData
          data-receive-point-by-arguments:
            access REC_RTE_R_ComM_BSBattTempInfo_tec_ComM_BSBattTempInfo: accessed-variable=RTE_R_ComM_BSBattTempInfo.tec_ComM_BSBattTempInfo
        DataServices_BS_base_information4_SOF_V2_ConditionCheckRead
        DataServices_BS_base_information4_SOF_V2_ReadData
          data-receive-point-by-arguments:
            access REC_RTE_R_ComM_BSSOFV2Info_tec_ComM_BSSOFV2Info: accessed-variable=RTE_R_ComM_BSSOFV2Info.tec_ComM_BSSOFV2Info
        DataServices_BS_base_information4_SOH_ConditionCheckRead
        DataServices_BS_base_information4_SOH_ReadData
          data-receive-point-by-arguments:
            access REC_RTE_R_ComM_BSBattSOHInfo_tec_ComM_BSBattSOHInfo: accessed-variable=RTE_R_ComM_BSBattSOHInfo.tec_ComM_BSBattSOHInfo
        DataServices_BS_base_information4_BS_SOC_ConditionCheckRead
        DataServices_BS_base_information4_BS_SOC_ReadData
          data-receive-point-by-arguments:
            access REC_RTE_R_ComM_BSBattSOC_pct_tec_ComM_BSBattSOC_pct: accessed-variable=RTE_R_ComM_BSBattSOC_pct.tec_ComM_BSBattSOC_pct
            access REC_SOC_LIN01_SOC_LIN01: accessed-variable=SOC_LIN01.SOC_LIN01
        DataServices_BS_base_information4_SOF_V1_ConditionCheckRead
        DataServices_BS_base_information4_SOF_V1_ReadData
          data-receive-point-by-arguments:
            access REC_RTE_R_ComM_BSSOFV1Info_tec_ComM_BSSOFV1Info: accessed-variable=RTE_R_ComM_BSSOFV1Info.tec_ComM_BSSOFV1Info
        DataServices_HV_part_fault_information_HV_part_fault_information1_WriteData
        DataServices_HV_part_fault_information_HV_part_fault_information1_ConditionCheckRead
        DataServices_HV_part_fault_information_HV_part_fault_information1_ReadData
          data-receive-point-by-arguments:
            access REC_RTE_R_ComM_BMSErrLvl_Enum_tec_ComM_BMSErrLvl_Enum: accessed-variable=RTE_R_ComM_BMSErrLvl_Enum.tec_ComM_BMSErrLvl_Enum
            access REC_RTE_R_ComM_DCDCErrLvl_Enum_tec_ComM_DCDCErrLvl_Enum: accessed-variable=RTE_R_ComM_DCDCErrLvl_Enum.tec_ComM_DCDCErrLvl_Enum
            access REC_RTE_R_ComM_OBCErrLvl_Enum_tec_ComM_OBCErrLvl_Enum: accessed-variable=RTE_R_ComM_OBCErrLvl_Enum.tec_ComM_OBCErrLvl_Enum
        DataServices_HV_part_fault_information_HV_part_fault_information3_WriteData
        DataServices_HV_part_fault_information_HV_part_fault_information3_ConditionCheckRead
        DataServices_HV_part_fault_information_HV_part_fault_information3_ReadData
          data-receive-point-by-arguments:
            access REC_RTE_R_ComM_ACUCrashOutpSts_Enum_tec_ComM_ACUCrashOutpSts_Enum: accessed-variable=RTE_R_ComM_ACUCrashOutpSts_Enum.tec_ComM_ACUCrashOutpSts_Enum
            access REC_RTE_R_ComM_BMSInslaErrLvl_Enum_tec_ComM_BMSInslaErrLvl_Enum: accessed-variable=RTE_R_ComM_BMSInslaErrLvl_Enum.tec_ComM_BMSInslaErrLvl_Enum
            access REC_RTE_R_ErrMgmt_VCUHVILErr_Flg_tec_ErrMgmt_VCUHVILErr_Flg: accessed-variable=RTE_R_ErrMgmt_VCUHVILErr_Flg.tec_ErrMgmt_VCUHVILErr_Flg
        DataServices_HV_part_fault_information_HV_part_fault_information2_WriteData
        DataServices_HV_part_fault_information_HV_part_fault_information2_ConditionCheckRead
        DataServices_HV_part_fault_information_HV_part_fault_information2_ReadData
          data-receive-point-by-arguments:
            access REC_RTE_R_ComM_MCUErrLvl_Enum_tec_ComM_MCUErrLvl_Enum: accessed-variable=RTE_R_ComM_MCUErrLvl_Enum.tec_ComM_MCUErrLvl_Enum
            access REC_RTE_R_ComM_TCUErrLvl_Enum_tec_ComM_TCUErrLvl_Enum: accessed-variable=RTE_R_ComM_TCUErrLvl_Enum.tec_ComM_TCUErrLvl_Enum
            access REC_RTE_R_ComM_BMSHVILSts_Flg_tec_ComM_BMSHVILSts_Flg: accessed-variable=RTE_R_ComM_BMSHVILSts_Flg.tec_ComM_BMSHVILSts_Flg
  swc implementation CtAp_DiagnosisApp_Implementation: behavior=CtAp_DiagnosisApp_InternalBehavior
